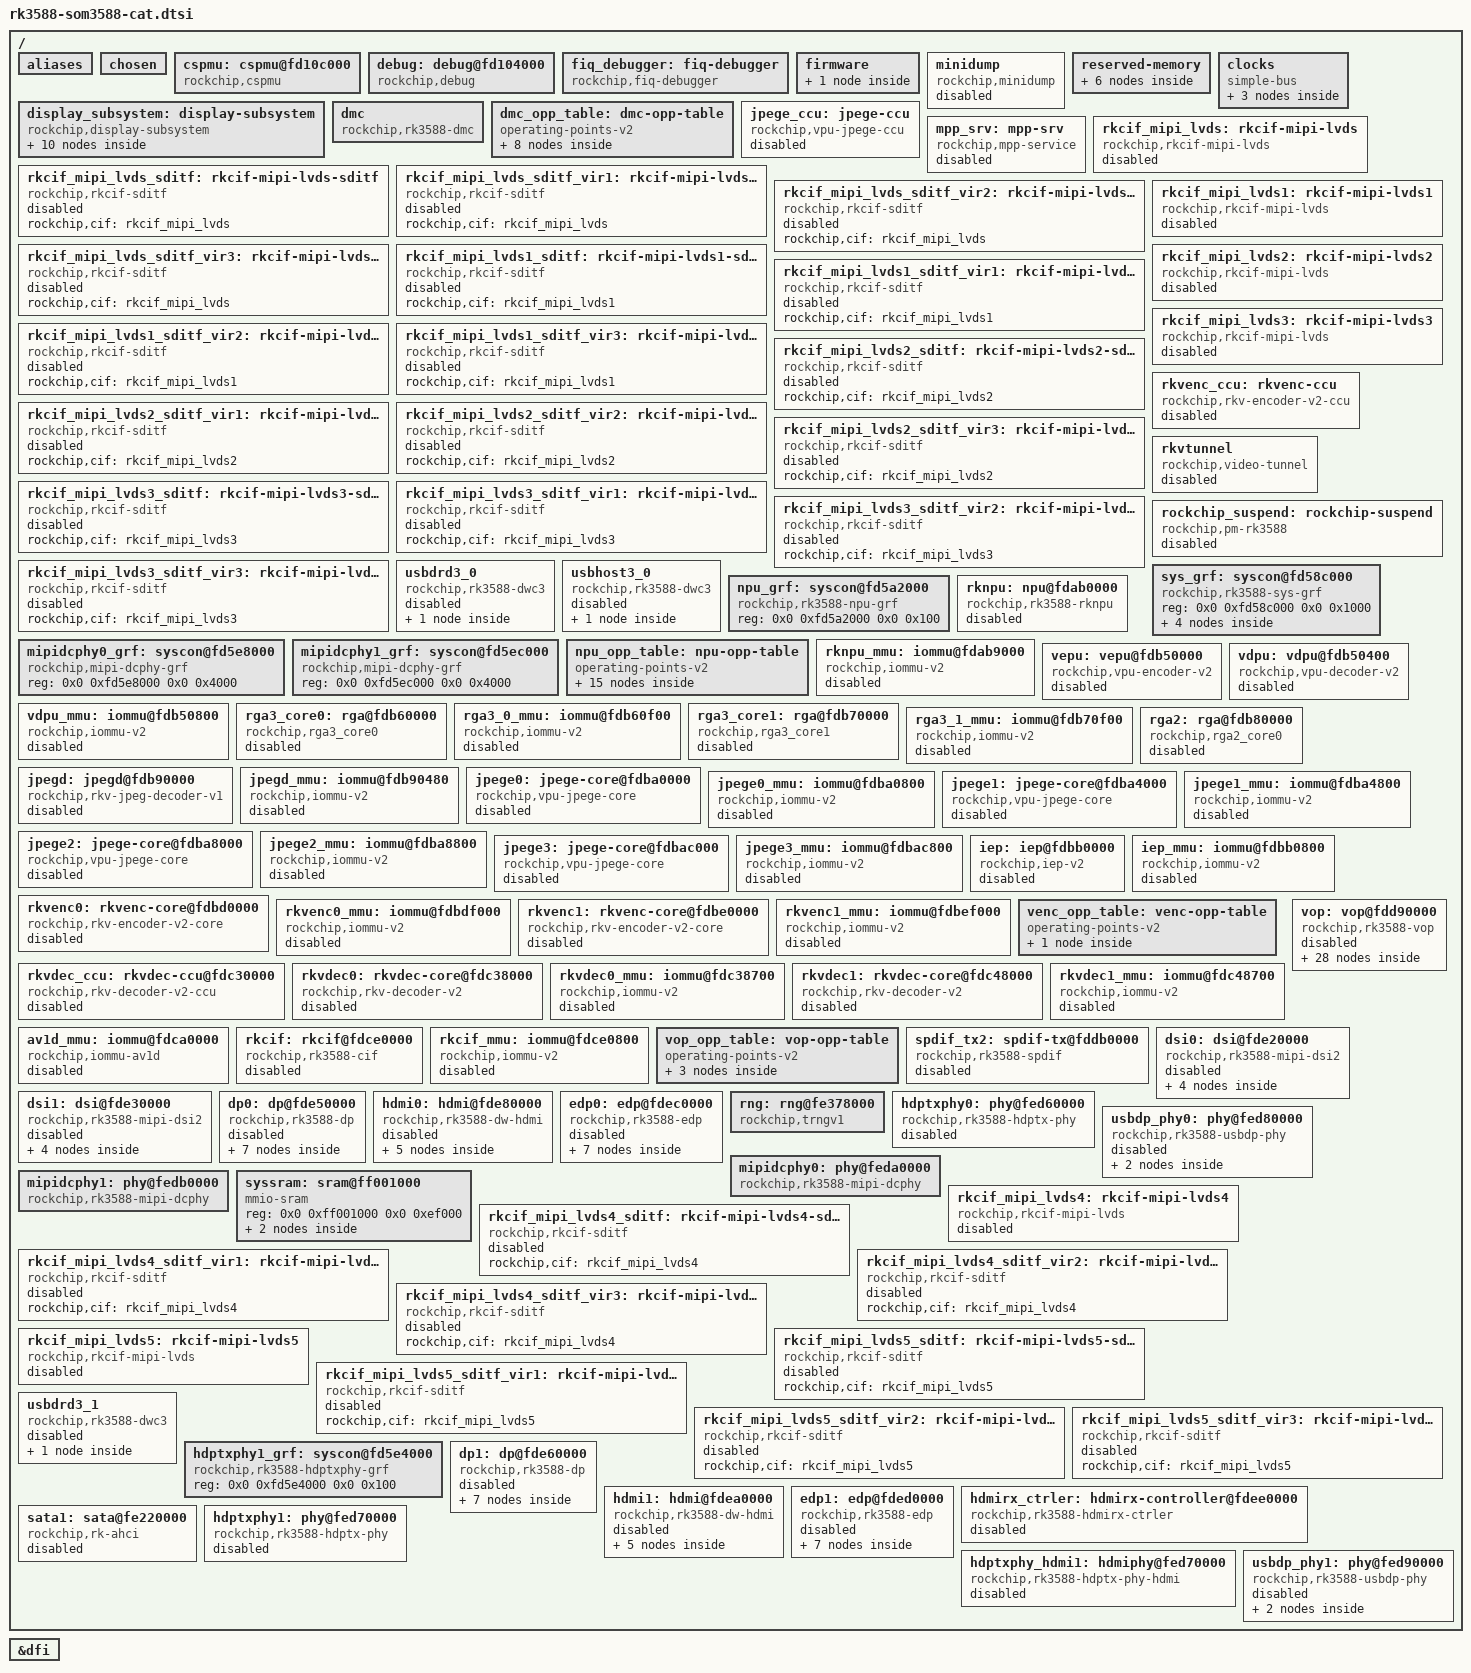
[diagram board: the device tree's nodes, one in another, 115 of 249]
// SPDX-License-Identifier: (GPL-2.0+ OR MIT)
/*
 * Copyright (c) 2022 Rockchip Electronics Co., Ltd.
 *
 */

#include "rk3588.dtsi"
#include "rk3588-linux.dtsi"
#include <dt-bindings/clock/rk3588-cru.h>
#include <dt-bindings/pinctrl/rockchip.h>
#include <dt-bindings/soc/rockchip,boot-mode.h>
#include <dt-bindings/soc/rockchip-system-status.h>
#include <dt-bindings/suspend/rockchip-rk3588.h>
#include <dt-bindings/phy/phy-snps-pcie3.h>

/ {
	aliases {
		mmc0 = &sdhci;
		mmc1 = &sdmmc;
		mmc2 = &sdio;
		rkcif_mipi_lvds0= &rkcif_mipi_lvds;
		rkcif_mipi_lvds1= &rkcif_mipi_lvds1;
		rkcif_mipi_lvds2= &rkcif_mipi_lvds2;
		rkcif_mipi_lvds3= &rkcif_mipi_lvds3;
		rkvdec0 = &rkvdec0;
		rkvdec1 = &rkvdec1;
		rkvenc0 = &rkvenc0;
		rkvenc1 = &rkvenc1;
		jpege0 = &jpege0;
		jpege1 = &jpege1;
		jpege2 = &jpege2;
		jpege3 = &jpege3;
		dp0 = &dp0;
		dp1 = &dp1;
		edp0 = &edp0;
		edp1 = &edp1;
		ethernet0 = &gmac0;
		hdptx0 = &hdptxphy0;
		hdptx1 = &hdptxphy1;
		hdptxhdmi0 = &hdptxphy_hdmi0;
		hdptxhdmi1 = &hdptxphy_hdmi1;
		hdmi0 = &hdmi0;
		hdmi1 = &hdmi1;
		hdmirx0 = &hdmirx_ctrler;
		rkcif_mipi_lvds4= &rkcif_mipi_lvds4;
		rkcif_mipi_lvds5= &rkcif_mipi_lvds5;
		usbdp0 = &usbdp_phy0;
		usbdp1 = &usbdp_phy1;
	};

	chosen: chosen {
		stdout-path = "serial2:1500000n8";
		bootargs = "earlycon=uart8250,mmio32,0xfeb50000 console=ttyFIQ0 irqchip.gicv3_pseudo_nmi=0 root=PARTUUID=614e0000-0000 rw rootwait rcupdate.rcu_expedited=1 rcu_nocbs=all";
	};

	cspmu: cspmu@fd10c000 {
		compatible = "rockchip,cspmu";
		reg = <0x0 0xfd10c000 0x0 0x1000>,
		      <0x0 0xfd10d000 0x0 0x1000>,
		      <0x0 0xfd10e000 0x0 0x1000>,
		      <0x0 0xfd10f000 0x0 0x1000>,
		      <0x0 0xfd12c000 0x0 0x1000>,
		      <0x0 0xfd12d000 0x0 0x1000>,
		      <0x0 0xfd12e000 0x0 0x1000>,
		      <0x0 0xfd12f000 0x0 0x1000>;
	};

	debug: debug@fd104000 {
		compatible = "rockchip,debug";
		reg = <0x0 0xfd104000 0x0 0x1000>,
		      <0x0 0xfd105000 0x0 0x1000>,
		      <0x0 0xfd106000 0x0 0x1000>,
		      <0x0 0xfd107000 0x0 0x1000>,
		      <0x0 0xfd124000 0x0 0x1000>,
		      <0x0 0xfd125000 0x0 0x1000>,
		      <0x0 0xfd126000 0x0 0x1000>,
		      <0x0 0xfd127000 0x0 0x1000>;
	};

	fiq_debugger: fiq-debugger {
		compatible = "rockchip,fiq-debugger";
		rockchip,serial-id = <2>;
		rockchip,wake-irq = <0>;
		/* If enable uart uses irq instead of fiq */
		rockchip,irq-mode-enable = <1>;
		rockchip,baudrate = <1500000>;  /* Only 115200 and 1500000 */
		interrupts = <GIC_SPI 423 IRQ_TYPE_LEVEL_LOW>;
		pinctrl-names = "default";
		pinctrl-0 = <&uart2m0_xfer>;
		status = "okay";
	};

	firmware {
		optee: optee {
			compatible = "linaro,optee-tz";
			method = "smc";
			//status = "disabled";
		};
	};

	minidump: minidump {
		compatible = "rockchip,minidump";
		smem-region = <&minidump_smem>;
		minidump-region = <&minidump_mem>;
		status = "disabled";
	};

	reserved-memory {
		#address-cells = <2>;
		#size-cells = <2>;
		ranges;

		cma {
			compatible = "shared-dma-pool";
			reusable;
			size = <0x0 (8 * 0x100000)>;
			linux,cma-default;
		};

		drm_logo: drm-logo@0 {
			compatible = "rockchip,drm-logo";
			reg = <0x0 0x0 0x0 0x0>;
		};

		drm_cubic_lut: drm-cubic-lut@0 {
			compatible = "rockchip,drm-cubic-lut";
			reg = <0x0 0x0 0x0 0x0>;
		};

		ramoops: ramoops@110000 {
			compatible = "ramoops";
			/* 0x110000 to 0x1f0000 is for ramoops */
			reg = <0x0 0x110000 0x0 0xe0000>;
			boot-log-size = <0x8000>;	/* do not change */
			boot-log-count = <0x1>;		/* do not change */
			console-size = <0x80000>;
			pmsg-size = <0x30000>;
			ftrace-size = <0x00000>;
			record-size = <0x14000>;
		};

		minidump_smem: minidump-smem@1f0000 {
			reg = <0x0 0x1f0000 0x0 0x100>;		/* do not change */
			no-map;
			status = "disabled";
		};

		minidump_mem: minidump-mem@c000000 {
			reg = <0x0 0x0c000000 0x0 0x2000000>;	/* changing according to your project */
			no-map;
			status = "disabled";
		};

	};

	clocks {
		compatible = "simple-bus";
		#address-cells = <2>;
		#size-cells = <2>;
		ranges;

		hclk_vo1: hclk_vo1@fd7c08ec {
			compatible = "rockchip,rk3588-clock-gate-link";
			reg = <0 0xfd7c08ec 0 0x10>;
			clock-names = "link";
			clocks = <&cru HCLK_VO1USB_TOP_ROOT>;
			#power-domain-cells = <1>;
			#clock-cells = <0>;
		};

		hclk_vo0: hclk_vo0@fd7c08dc {
			compatible = "rockchip,rk3588-clock-gate-link";
			reg = <0 0xfd7c08dc 0 0x10>;
			clock-names = "link";
			clocks = <&cru HCLK_VOP_ROOT>;
			#power-domain-cells = <1>;
			#clock-cells = <0>;
		};

		mclkout_i2s0: mclkout-i2s0@fd58c318 {
			compatible = "rockchip,clk-out";
			reg = <0 0xfd58c318 0 0x4>;
			clocks = <&cru I2S0_8CH_MCLKOUT>;
			#clock-cells = <0>;
			clock-output-names = "i2s0_mclkout_to_io";
			power-domains = <&power RK3588_PD_AUDIO>;
			rockchip,bit-shift = <0>;
			rockchip,bit-set-to-disable;
		};
	};

	display_subsystem: display-subsystem {
		compatible = "rockchip,display-subsystem";
		ports = <&vop_out>;

		route {
			route_dp0: route-dp0 {
				status = "disabled";
				logo,uboot = "logo.bmp";
				logo,kernel = "logo_kernel.bmp";
				logo,mode = "center";
				charge_logo,mode = "center";
				connect = <&vp1_out_dp0>;
			};

			route_dsi0: route-dsi0 {
				status = "disabled";
				logo,uboot = "logo.bmp";
				logo,kernel = "logo_kernel.bmp";
				logo,mode = "center";
				charge_logo,mode = "center";
				connect = <&vp3_out_dsi0>;
			};

			route_dsi1: route-dsi1 {
				status = "disabled";
				logo,uboot = "logo.bmp";
				logo,kernel = "logo_kernel.bmp";
				logo,mode = "center";
				charge_logo,mode = "center";
				connect = <&vp3_out_dsi1>;
			};

			route_edp0: route-edp0 {
				status = "disabled";
				logo,uboot = "logo.bmp";
				logo,kernel = "logo_kernel.bmp";
				logo,mode = "center";
				charge_logo,mode = "center";
				connect = <&vp2_out_edp0>;
			};

			route_edp1: route-edp1 {
				status = "disabled";
				logo,uboot = "logo.bmp";
				logo,kernel = "logo_kernel.bmp";
				logo,mode = "center";
				charge_logo,mode = "center";
			};

			route_hdmi0: route-hdmi0 {
				status = "disabled";
				logo,uboot = "logo.bmp";
				logo,kernel = "logo_kernel.bmp";
				logo,mode = "center";
				charge_logo,mode = "center";
				connect = <&vp0_out_hdmi0>;
			};

			route_rgb: route-rgb {
				status = "disabled";
				logo,uboot = "logo.bmp";
				logo,kernel = "logo_kernel.bmp";
				logo,mode = "center";
				charge_logo,mode = "center";
				connect = <&vp3_out_rgb>;
			};
		};
	};

	dmc: dmc {
		compatible = "rockchip,rk3588-dmc";
		interrupts = <GIC_SPI 73 IRQ_TYPE_LEVEL_HIGH>;
		interrupt-names = "complete";
		devfreq-events = <&dfi>;
		clocks = <&scmi_clk 4>;
		clock-names = "dmc_clk";
		operating-points-v2 = <&dmc_opp_table>;
		upthreshold = <25>;
		downdifferential = <20>;
		system-status-level = <
			/*system status         freq level*/
			SYS_STATUS_NORMAL       DMC_FREQ_LEVEL_MID_HIGH
			SYS_STATUS_REBOOT       DMC_FREQ_LEVEL_HIGH
			SYS_STATUS_SUSPEND      DMC_FREQ_LEVEL_LOW
			SYS_STATUS_VIDEO_4K     DMC_FREQ_LEVEL_MID_HIGH
			SYS_STATUS_VIDEO_4K_10B DMC_FREQ_LEVEL_MID_HIGH
			SYS_STATUS_VIDEO_SVEP   DMC_FREQ_LEVEL_MID_HIGH
			SYS_STATUS_BOOST        DMC_FREQ_LEVEL_HIGH
			SYS_STATUS_ISP          DMC_FREQ_LEVEL_HIGH
			SYS_STATUS_PERFORMANCE  DMC_FREQ_LEVEL_HIGH
			SYS_STATUS_DUALVIEW     DMC_FREQ_LEVEL_HIGH
			SYS_STATUS_HDMIRX       DMC_FREQ_LEVEL_HIGH
			SYS_STATUS_DEEP_SUSPEND DMC_FREQ_LEVEL_HIGH
		>;
		auto-freq-en = <1>;
		status = "disabled";
	};

	dmc_opp_table: dmc-opp-table {
		compatible = "operating-points-v2";

		nvmem-cells = <&log_leakage>, <&dmc_opp_info>, <&specification_serial_number>;
		nvmem-cell-names = "leakage", "opp-info", "specification_serial_number";
		rockchip,supported-hw;

		rockchip,leakage-voltage-sel = <
			1	31	0
			32	44	1
			45	57	2
			58	254	3
		>;
		rockchip,temp-hysteresis = <5000>;
		rockchip,low-temp = <15000>;
		rockchip,low-temp-min-volt = <750000>;

		/* RK3588 dmc OPPs */
		opp-528000000 {
			opp-supported-hw = <0xf9 0xffff>;
			opp-hz = /bits/ 64 <528000000>;
			opp-microvolt = <675000 675000 875000>,
					<725000 725000 800000>;
			opp-microvolt-L1 = <675000 675000 875000>,
					   <700000 700000 800000>;
			opp-microvolt-L2 = <675000 675000 875000>,
					   <687500 687500 800000>;
			opp-microvolt-L3 = <675000 675000 875000>,
					   <675000 675000 800000>;
		};
		opp-1068000000 {
			opp-supported-hw = <0xf9 0xffff>;
			opp-hz = /bits/ 64 <1068000000>;
			opp-microvolt = <725000 725000 875000>,
					<737500 737500 800000>;
			opp-microvolt-L1 = <700000 700000 875000>,
					   <712500 712500 800000>;
			opp-microvolt-L2 = <675000 675000 875000>,
					   <700000 700000 800000>;
			opp-microvolt-L3 = <675000 675000 875000>,
					   <687500 687500 800000>;
		};
		opp-1560000000 {
			opp-supported-hw = <0xf9 0xffff>;
			opp-hz = /bits/ 64 <1560000000>;
			opp-microvolt = <800000 800000 875000>,
					<750000 750000 800000>;
			opp-microvolt-L1 = <775000 775000 875000>,
					   <725000 725000 800000>;
			opp-microvolt-L2 = <750000 750000 875000>,
					   <712500 712500 800000>;
			opp-microvolt-L3 = <725000 725000 875000>,
					   <700000 700000 800000>;
		};
		opp-2750000000 {
			opp-supported-hw = <0xf9 0xffff>;
			opp-hz = /bits/ 64 <2750000000>;
			opp-microvolt = <875000 875000 875000>,
					<750000 750000 800000>;
			opp-microvolt-L1 = <850000 850000 875000>,
					   <750000 750000 800000>;
			opp-microvolt-L2 = <837500 837500 875000>,
					   <725000 725000 800000>;
			opp-microvolt-L3 = <825000 820000 875000>,
					   <700000 700000 800000>;
		};

		/* RK3588J/M dmc OPPs */
		opp-j-m-528000000 {
			opp-supported-hw = <0x06 0xffff>;
			opp-hz = /bits/ 64 <528000000>;
			opp-microvolt = <750000 750000 875000>,
					<750000 750000 800000>;
		};
		opp-j-m-1068000000 {
			opp-supported-hw = <0x06 0xffff>;
			opp-hz = /bits/ 64 <1068000000>;
			opp-microvolt = <750000 750000 875000>,
					<750000 750000 800000>;
		};
		opp-j-m-1560000000 {
			opp-supported-hw = <0x06 0xffff>;
			opp-hz = /bits/ 64 <1560000000>;
			opp-microvolt = <800000 800000 875000>,
					<750000 750000 800000>;
			opp-microvolt-L1 = <775000 775000 875000>,
					   <750000 750000 800000>;
			opp-microvolt-L2 = <750000 750000 875000>,
					   <750000 750000 800000>;
			opp-microvolt-L3 = <750000 750000 875000>,
					   <750000 750000 800000>;
		};
		opp-j-m-2750000000 {
			opp-supported-hw = <0x06 0xffff>;
			opp-hz = /bits/ 64 <2750000000>;
			opp-microvolt = <875000 875000 875000>,
					<750000 750000 800000>;
			opp-microvolt-L1 = <850000 850000 875000>,
					   <750000 750000 800000>;
			opp-microvolt-L2 = <837500 837500 875000>,
					   <750000 750000 800000>;
			opp-microvolt-L3 = <825000 820000 875000>,
					   <750000 750000 800000>;
		};
	};

	jpege_ccu: jpege-ccu {
		compatible = "rockchip,vpu-jpege-ccu";
		status = "disabled";
	};

	mpp_srv: mpp-srv {
		compatible = "rockchip,mpp-service";
		rockchip,taskqueue-count = <12>;
		rockchip,resetgroup-count = <1>;
		status = "disabled";
	};

	rkcif_mipi_lvds: rkcif-mipi-lvds {
		compatible = "rockchip,rkcif-mipi-lvds";
		rockchip,hw = <&rkcif>;
		iommus = <&rkcif_mmu>;
		status = "disabled";
	};

	rkcif_mipi_lvds_sditf: rkcif-mipi-lvds-sditf {
		compatible = "rockchip,rkcif-sditf";
		rockchip,cif = <&rkcif_mipi_lvds>;
		status = "disabled";
	};

	rkcif_mipi_lvds_sditf_vir1: rkcif-mipi-lvds-sditf-vir1 {
		compatible = "rockchip,rkcif-sditf";
		rockchip,cif = <&rkcif_mipi_lvds>;
		status = "disabled";
	};

	rkcif_mipi_lvds_sditf_vir2: rkcif-mipi-lvds-sditf-vir2 {
		compatible = "rockchip,rkcif-sditf";
		rockchip,cif = <&rkcif_mipi_lvds>;
		status = "disabled";
	};

	rkcif_mipi_lvds_sditf_vir3: rkcif-mipi-lvds-sditf-vir3 {
		compatible = "rockchip,rkcif-sditf";
		rockchip,cif = <&rkcif_mipi_lvds>;
		status = "disabled";
	};

	rkcif_mipi_lvds1: rkcif-mipi-lvds1 {
		compatible = "rockchip,rkcif-mipi-lvds";
		rockchip,hw = <&rkcif>;
		iommus = <&rkcif_mmu>;
		status = "disabled";
	};

	rkcif_mipi_lvds1_sditf: rkcif-mipi-lvds1-sditf {
		compatible = "rockchip,rkcif-sditf";
		rockchip,cif = <&rkcif_mipi_lvds1>;
		status = "disabled";
	};

	rkcif_mipi_lvds1_sditf_vir1: rkcif-mipi-lvds1-sditf-vir1 {
		compatible = "rockchip,rkcif-sditf";
		rockchip,cif = <&rkcif_mipi_lvds1>;
		status = "disabled";
	};

	rkcif_mipi_lvds1_sditf_vir2: rkcif-mipi-lvds1-sditf-vir2 {
		compatible = "rockchip,rkcif-sditf";
		rockchip,cif = <&rkcif_mipi_lvds1>;
		status = "disabled";
	};

	rkcif_mipi_lvds1_sditf_vir3: rkcif-mipi-lvds1-sditf-vir3 {
		compatible = "rockchip,rkcif-sditf";
		rockchip,cif = <&rkcif_mipi_lvds1>;
		status = "disabled";
	};

	rkcif_mipi_lvds2: rkcif-mipi-lvds2 {
		compatible = "rockchip,rkcif-mipi-lvds";
		rockchip,hw = <&rkcif>;
		iommus = <&rkcif_mmu>;
		status = "disabled";
	};

	rkcif_mipi_lvds2_sditf: rkcif-mipi-lvds2-sditf {
		compatible = "rockchip,rkcif-sditf";
		rockchip,cif = <&rkcif_mipi_lvds2>;
		status = "disabled";
	};

	rkcif_mipi_lvds2_sditf_vir1: rkcif-mipi-lvds2-sditf-vir1 {
		compatible = "rockchip,rkcif-sditf";
		rockchip,cif = <&rkcif_mipi_lvds2>;
		status = "disabled";
	};

	rkcif_mipi_lvds2_sditf_vir2: rkcif-mipi-lvds2-sditf-vir2 {
		compatible = "rockchip,rkcif-sditf";
		rockchip,cif = <&rkcif_mipi_lvds2>;
		status = "disabled";
	};

	rkcif_mipi_lvds2_sditf_vir3: rkcif-mipi-lvds2-sditf-vir3 {
		compatible = "rockchip,rkcif-sditf";
		rockchip,cif = <&rkcif_mipi_lvds2>;
		status = "disabled";
	};

	rkcif_mipi_lvds3: rkcif-mipi-lvds3 {
		compatible = "rockchip,rkcif-mipi-lvds";
		rockchip,hw = <&rkcif>;
		iommus = <&rkcif_mmu>;
		status = "disabled";
	};

	rkcif_mipi_lvds3_sditf: rkcif-mipi-lvds3-sditf {
		compatible = "rockchip,rkcif-sditf";
		rockchip,cif = <&rkcif_mipi_lvds3>;
		status = "disabled";
	};

	rkcif_mipi_lvds3_sditf_vir1: rkcif-mipi-lvds3-sditf-vir1 {
		compatible = "rockchip,rkcif-sditf";
		rockchip,cif = <&rkcif_mipi_lvds3>;
		status = "disabled";
	};

	rkcif_mipi_lvds3_sditf_vir2: rkcif-mipi-lvds3-sditf-vir2 {
		compatible = "rockchip,rkcif-sditf";
		rockchip,cif = <&rkcif_mipi_lvds3>;
		status = "disabled";
	};

	rkcif_mipi_lvds3_sditf_vir3: rkcif-mipi-lvds3-sditf-vir3 {
		compatible = "rockchip,rkcif-sditf";
		rockchip,cif = <&rkcif_mipi_lvds3>;
		status = "disabled";
	};

	rkvenc_ccu: rkvenc-ccu {
		compatible = "rockchip,rkv-encoder-v2-ccu";
		status = "disabled";
	};

	rkvtunnel: rkvtunnel {
		compatible = "rockchip,video-tunnel";
		status = "disabled";
	};

	rockchip_suspend: rockchip-suspend {
		compatible = "rockchip,pm-rk3588";
		status = "disabled";
		rockchip,sleep-debug-en = <0>;
		rockchip,sleep-mode-config = <
			(0
			| RKPM_SLP_ARMOFF_LOGOFF
			| RKPM_SLP_PMU_PMUALIVE_32K
			| RKPM_SLP_PMU_DIS_OSC
			| RKPM_SLP_32K_EXT
			)
		>;
		rockchip,wakeup-config = <
			(0
			| RKPM_GPIO_WKUP_EN
			)
		>;
		power-domains = <&power RK3588_PD_USB>;
	};

	usbdrd3_0: usbdrd3_0 {
		compatible = "rockchip,rk3588-dwc3", "rockchip,rk3399-dwc3";
		clocks = <&cru REF_CLK_USB3OTG0>, <&cru SUSPEND_CLK_USB3OTG0>,
			 <&cru ACLK_USB3OTG0>;
		clock-names = "ref", "suspend", "bus";
		#address-cells = <2>;
		#size-cells = <2>;
		ranges;
		status = "disabled";

		usbdrd_dwc3_0: usb@fc000000 {
			compatible = "snps,dwc3";
			reg = <0x0 0xfc000000 0x0 0x400000>;
			interrupts = <GIC_SPI 220 IRQ_TYPE_LEVEL_HIGH>;
			power-domains = <&power RK3588_PD_USB>;
			resets = <&cru SRST_A_USB3OTG0>;
			reset-names = "usb3-otg";
			dr_mode = "otg";
			phys = <&u2phy0_otg>, <&usbdp_phy0_u3>;
			phy-names = "usb2-phy", "usb3-phy";
			phy_type = "utmi_wide";
			snps,dis_enblslpm_quirk;
			snps,dis-u1-entry-quirk;
			snps,dis-u2-entry-quirk;
			snps,dis-u2-freeclk-exists-quirk;
			snps,dis-del-phy-power-chg-quirk;
			snps,dis-tx-ipgap-linecheck-quirk;
			snps,parkmode-disable-hs-quirk;
			snps,parkmode-disable-ss-quirk;
			quirk-skip-phy-init;
			status = "disabled";
		};
	};

	usbhost3_0: usbhost3_0 {
		compatible = "rockchip,rk3588-dwc3", "rockchip,rk3399-dwc3";
		clocks = <&cru REF_CLK_USB3OTG2>, <&cru SUSPEND_CLK_USB3OTG2>,
			 <&cru ACLK_USB3OTG2>, <&cru CLK_UTMI_OTG2>,
			 <&cru PCLK_PHP_ROOT>, <&cru CLK_PIPEPHY2_PIPE_U3_G>;
		clock-names = "ref", "suspend", "bus", "utmi", "php", "pipe";
		#address-cells = <2>;
		#size-cells = <2>;
		ranges;
		status = "disabled";

		usbhost_dwc3_0: usb@fcd00000 {
			compatible = "snps,dwc3";
			reg = <0x0 0xfcd00000 0x0 0x400000>;
			interrupts = <GIC_SPI 222 IRQ_TYPE_LEVEL_HIGH>;
			resets = <&cru SRST_A_USB3OTG2>;
			reset-names = "usb3-host";
			dr_mode = "host";
			phys = <&combphy2_psu PHY_TYPE_USB3>;
			phy-names = "usb3-phy";
			phy_type = "utmi_wide";
			snps,dis_enblslpm_quirk;
			snps,dis-u2-freeclk-exists-quirk;
			snps,dis-del-phy-power-chg-quirk;
			snps,dis-tx-ipgap-linecheck-quirk;
			snps,dis_rxdet_inp3_quirk;
			snps,parkmode-disable-hs-quirk;
			snps,parkmode-disable-ss-quirk;
			status = "disabled";
		};
	};

	sys_grf: syscon@fd58c000 {
		compatible = "rockchip,rk3588-sys-grf", "syscon", "simple-mfd";
		reg = <0x0 0xfd58c000 0x0 0x1000>;

		rgb: rgb {
			compatible = "rockchip,rk3588-rgb";
			pinctrl-names = "default";
			pinctrl-0 = <&bt1120_pins>;
			status = "disabled";

			ports {
				#address-cells = <1>;
				#size-cells = <0>;

				port@0 {
					reg = <0>;
					#address-cells = <1>;
					#size-cells = <0>;

					rgb_in_vp3: endpoint@2 {
						reg = <2>;
						remote-endpoint = <&vp3_out_rgb>;
						status = "disabled";
					};
				};
			};
		};
	};
	
	npu_grf: syscon@fd5a2000 {
		compatible = "rockchip,rk3588-npu-grf", "syscon";
		reg = <0x0 0xfd5a2000 0x0 0x100>;
	};

	mipidcphy0_grf: syscon@fd5e8000 {
		compatible = "rockchip,mipi-dcphy-grf", "syscon";
		reg = <0x0 0xfd5e8000 0x0 0x4000>;
	};

	mipidcphy1_grf: syscon@fd5ec000 {
		compatible = "rockchip,mipi-dcphy-grf", "syscon";
		reg = <0x0 0xfd5ec000 0x0 0x4000>;
	};

	rknpu: npu@fdab0000 {
		compatible = "rockchip,rk3588-rknpu";
		reg = <0x0 0xfdab0000 0x0 0x10000>,
		      <0x0 0xfdac0000 0x0 0x10000>,
		      <0x0 0xfdad0000 0x0 0x10000>;
		interrupts = <GIC_SPI 110 IRQ_TYPE_LEVEL_HIGH>,
			     <GIC_SPI 111 IRQ_TYPE_LEVEL_HIGH>,
			     <GIC_SPI 112 IRQ_TYPE_LEVEL_HIGH>;
		interrupt-names = "npu0_irq", "npu1_irq", "npu2_irq";
		clocks = <&scmi_clk SCMI_CLK_NPU>, <&cru ACLK_NPU0>,
			 <&cru ACLK_NPU1>, <&cru ACLK_NPU2>,
			 <&cru HCLK_NPU0>, <&cru HCLK_NPU1>,
			 <&cru HCLK_NPU2>, <&cru PCLK_NPU_ROOT>;
		clock-names = "clk_npu", "aclk0",
			      "aclk1", "aclk2",
			      "hclk0", "hclk1",
			      "hclk2", "pclk";
		assigned-clocks = <&scmi_clk SCMI_CLK_NPU>;
		assigned-clock-rates = <200000000>;
		resets = <&cru SRST_A_RKNN0>, <&cru SRST_A_RKNN1>, <&cru SRST_A_RKNN2>,
			 <&cru SRST_H_RKNN0>, <&cru SRST_H_RKNN1>, <&cru SRST_H_RKNN2>;
		reset-names = "srst_a0", "srst_a1", "srst_a2",
			      "srst_h0", "srst_h1", "srst_h2";
		power-domains = <&power RK3588_PD_NPUTOP>,
				<&power RK3588_PD_NPU1>,
				<&power RK3588_PD_NPU2>;
		power-domain-names = "npu0", "npu1", "npu2";
		operating-points-v2 = <&npu_opp_table>;
		iommus = <&rknpu_mmu>;
		status = "disabled";
	};

	rknpu: npu@fdab0000 {
		compatible = "rockchip,rk3588-rknpu";
		reg = <0x0 0xfdab0000 0x0 0x10000>,
		      <0x0 0xfdac0000 0x0 0x10000>,
		      <0x0 0xfdad0000 0x0 0x10000>;
		interrupts = <GIC_SPI 110 IRQ_TYPE_LEVEL_HIGH>,
			     <GIC_SPI 111 IRQ_TYPE_LEVEL_HIGH>,
			     <GIC_SPI 112 IRQ_TYPE_LEVEL_HIGH>;
		interrupt-names = "npu0_irq", "npu1_irq", "npu2_irq";
		clocks = <&scmi_clk SCMI_CLK_NPU>, <&cru ACLK_NPU0>,
			 <&cru ACLK_NPU1>, <&cru ACLK_NPU2>,
			 <&cru HCLK_NPU0>, <&cru HCLK_NPU1>,
			 <&cru HCLK_NPU2>, <&cru PCLK_NPU_ROOT>;
		clock-names = "clk_npu", "aclk0",
			      "aclk1", "aclk2",
			      "hclk0", "hclk1",
			      "hclk2", "pclk";
		assigned-clocks = <&scmi_clk SCMI_CLK_NPU>;
		assigned-clock-rates = <200000000>;
		resets = <&cru SRST_A_RKNN0>, <&cru SRST_A_RKNN1>, <&cru SRST_A_RKNN2>,
			 <&cru SRST_H_RKNN0>, <&cru SRST_H_RKNN1>, <&cru SRST_H_RKNN2>;
		reset-names = "srst_a0", "srst_a1", "srst_a2",
			      "srst_h0", "srst_h1", "srst_h2";
		power-domains = <&power RK3588_PD_NPUTOP>,
				<&power RK3588_PD_NPU1>,
				<&power RK3588_PD_NPU2>;
		power-domain-names = "npu0", "npu1", "npu2";
		operating-points-v2 = <&npu_opp_table>;
		iommus = <&rknpu_mmu>;
		status = "disabled";
	};

	npu_opp_table: npu-opp-table {
		compatible = "operating-points-v2";

		nvmem-cells = <&npu_leakage>, <&npu_opp_info>, <&specification_serial_number>;
		nvmem-cell-names = "leakage", "opp-info", "specification_serial_number";
		rockchip,supported-hw;

		rockchip,pvtm-hw = <0x06>;
		rockchip,pvtm-voltage-sel-hw = <
			0	799	0
			800	819	1
			820	844	2
			845	869	3
			870	894	4
			895	9999	5
		>;
		rockchip,pvtm-voltage-sel = <
			0	815	0
			816	835	1
			836	860	2
			861	885	3
			886	910	4
			911	9999	5
		>;
		rockchip,pvtm-pvtpll;
		rockchip,pvtm-offset = <0x50>;
		rockchip,pvtm-sample-time = <1100>;
		rockchip,pvtm-freq = <800000>;
		rockchip,pvtm-volt = <750000>;
		rockchip,pvtm-ref-temp = <25>;
		rockchip,pvtm-temp-prop = <(-113) (-113)>;
		rockchip,pvtm-thermal-zone = "npu-thermal";

		rockchip,opp-clocks = <&cru PCLK_NPU_GRF>, <&cru HCLK_NPU_ROOT>;
		rockchip,grf = <&npu_grf>;
		volt-mem-read-margin = <
			855000	1
			765000	2
			675000	3
			495000	4
		>;
		low-volt-mem-read-margin = <4>;
		intermediate-threshold-freq = <500000>;	/* KHz*/
		rockchip,init-freq = <1000000>;		/* KHz */

		rockchip,temp-hysteresis = <5000>;
		rockchip,low-temp = <15000>;
		rockchip,low-temp-min-volt = <750000>;
		rockchip,high-temp = <85000>;
		rockchip,high-temp-max-freq = <800000>;

		/* RK3588 npu OPPs */
		opp-300000000 {
			opp-supported-hw = <0xf9 0xffff>;
			opp-hz = /bits/ 64 <300000000>;
			opp-microvolt = <700000 700000 850000>,
					<700000 700000 850000>;
			opp-microvolt-L1 = <687500 687500 850000>,
					   <687500 687500 850000>;
			opp-microvolt-L2 = <675000 675000 850000>,
					   <675000 675000 850000>;
			opp-microvolt-L3 = <675000 675000 850000>,
					   <675000 675000 850000>;
			opp-microvolt-L4 = <675000 675000 850000>,
					   <675000 675000 850000>;
			opp-microvolt-L5 = <675000 675000 850000>,
					   <675000 675000 850000>;
		};
		opp-400000000 {
			opp-supported-hw = <0xf9 0xffff>;
			opp-hz = /bits/ 64 <400000000>;
			opp-microvolt = <700000 700000 850000>,
					<700000 700000 850000>;
			opp-microvolt-L1 = <687500 687500 850000>,
					   <687500 687500 850000>;
			opp-microvolt-L2 = <675000 675000 850000>,
					   <675000 675000 850000>;
			opp-microvolt-L3 = <675000 675000 850000>,
					   <675000 675000 850000>;
			opp-microvolt-L4 = <675000 675000 850000>,
					   <675000 675000 850000>;
			opp-microvolt-L5 = <675000 675000 850000>,
					   <675000 675000 850000>;
		};
		opp-500000000 {
			opp-supported-hw = <0xf9 0xffff>;
			opp-hz = /bits/ 64 <500000000>;
			opp-microvolt = <700000 700000 850000>,
					<700000 700000 850000>;
			opp-microvolt-L1 = <687500 687500 850000>,
					   <687500 687500 850000>;
			opp-microvolt-L2 = <675000 675000 850000>,
					   <675000 675000 850000>;
			opp-microvolt-L3 = <675000 675000 850000>,
					   <675000 675000 850000>;
			opp-microvolt-L4 = <675000 675000 850000>,
					   <675000 675000 850000>;
			opp-microvolt-L5 = <675000 675000 850000>,
					   <675000 675000 850000>;
		};
		opp-600000000 {
			opp-supported-hw = <0xf9 0xffff>;
			opp-hz = /bits/ 64 <600000000>;
			opp-microvolt = <700000 700000 850000>,
					<700000 700000 850000>;
			opp-microvolt-L1 = <687500 687500 850000>,
					   <687500 687500 850000>;
			opp-microvolt-L2 = <675000 675000 850000>,
					   <675000 675000 850000>;
			opp-microvolt-L3 = <675000 675000 850000>,
					   <675000 675000 850000>;
			opp-microvolt-L4 = <675000 675000 850000>,
					   <675000 675000 850000>;
			opp-microvolt-L5 = <675000 675000 850000>,
					   <675000 675000 850000>;
		};
		opp-700000000 {
			opp-supported-hw = <0xf9 0xffff>;
			opp-hz = /bits/ 64 <700000000>;
			opp-microvolt = <700000 700000 850000>,
					<700000 700000 850000>;
			opp-microvolt-L3 = <687500 687500 850000>,
					   <687500 687500 850000>;
			opp-microvolt-L4 = <675000 675000 850000>,
					   <675000 675000 850000>;
			opp-microvolt-L5 = <675000 675000 850000>,
					   <675000 675000 850000>;
		};
		opp-800000000 {
			opp-supported-hw = <0xf9 0xffff>;
			opp-hz = /bits/ 64 <800000000>;
			opp-microvolt = <750000 750000 850000>,
					<750000 750000 850000>;
			opp-microvolt-L2 = <737500 737500 850000>,
					   <737500 737500 850000>;
			opp-microvolt-L3 = <725000 725000 850000>,
					   <725000 725000 850000>;
			opp-microvolt-L4 = <712500 712500 850000>,
					   <712500 712500 850000>;
			opp-microvolt-L5 = <700000 700000 850000>,
					   <700000 700000 850000>;
		};
		opp-900000000 {
			opp-supported-hw = <0xf9 0xffff>;
			opp-hz = /bits/ 64 <900000000>;
			opp-microvolt = <800000 800000 850000>,
					<800000 800000 850000>;
			opp-microvolt-L1 = <787500 787500 850000>,
					   <787500 787500 850000>;
			opp-microvolt-L2 = <775000 775000 850000>,
					   <775000 775000 850000>;
			opp-microvolt-L3 = <762500 762500 850000>,
					   <762500 762500 850000>;
			opp-microvolt-L4 = <750000 750000 850000>,
					   <750000 750000 850000>;
			opp-microvolt-L5 = <737500 737500 850000>,
					   <737500 737500 850000>;
		};
		opp-1000000000 {
			opp-supported-hw = <0xf9 0xffff>;
			opp-hz = /bits/ 64 <1000000000>;
			opp-microvolt = <850000 850000 850000>,
					<850000 850000 850000>;
			opp-microvolt-L1 = <837500 837500 850000>,
					   <837500 837500 850000>;
			opp-microvolt-L2 = <825000 825000 850000>,
					   <825000 825000 850000>;
			opp-microvolt-L3 = <812500 812500 850000>,
					   <812500 812500 850000>;
			opp-microvolt-L4 = <800000 800000 850000>,
					   <800000 800000 850000>;
			opp-microvolt-L5 = <787500 787500 850000>,
					   <787500 787500 850000>;
		};

		/* RK3588J/M npu OPPs */
		opp-j-m-300000000 {
			opp-supported-hw = <0x06 0xffff>;
			opp-hz = /bits/ 64 <300000000>;
			opp-microvolt = <750000 750000 850000>,
					<750000 750000 850000>;
		};
		opp-j-m-400000000 {
			opp-supported-hw = <0x06 0xffff>;
			opp-hz = /bits/ 64 <400000000>;
			opp-microvolt = <750000 750000 850000>,
					<750000 750000 850000>;
		};
		opp-j-m-500000000 {
			opp-supported-hw = <0x06 0xffff>;
			opp-hz = /bits/ 64 <500000000>;
			opp-microvolt = <750000 750000 850000>,
					<750000 750000 850000>;
		};
		opp-j-m-600000000 {
			opp-supported-hw = <0x06 0xffff>;
			opp-hz = /bits/ 64 <600000000>;
			opp-microvolt = <750000 750000 850000>,
					<750000 750000 850000>;
		};
		opp-j-m-700000000 {
			opp-supported-hw = <0x06 0xffff>;
			opp-hz = /bits/ 64 <700000000>;
			opp-microvolt = <750000 750000 850000>,
					<750000 750000 850000>;
		};
		opp-j-m-800000000 {
			opp-supported-hw = <0x06 0xffff>;
			opp-hz = /bits/ 64 <800000000>;
			opp-microvolt = <750000 750000 850000>,
					<750000 750000 850000>;
		};
		opp-j-m-950000000 {
			opp-supported-hw = <0x06 0xffff>;
			opp-hz = /bits/ 64 <950000000>;
			opp-microvolt = <837500 837500 850000>,
					<837500 837500 850000>;
			opp-microvolt-L1 = <825000 825000 850000>,
					   <825000 825000 850000>;
			opp-microvolt-L2 = <812500 812500 850000>,
					   <812500 812500 850000>;
			opp-microvolt-L3 = <800000 800000 850000>,
					   <800000 800000 850000>;
			opp-microvolt-L4 = <787500 787500 850000>,
					   <787500 787500 850000>;
			opp-microvolt-L5 = <775000 775000 850000>,
					   <775000 775000 850000>;
		};
	};

	rknpu_mmu: iommu@fdab9000 {
		compatible = "rockchip,iommu-v2";
		reg = <0x0 0xfdab9000 0x0 0x100>,
		      <0x0 0xfdaba000 0x0 0x100>,
		      <0x0 0xfdaca000 0x0 0x100>,
		      <0x0 0xfdada000 0x0 0x100>;
		interrupts = <GIC_SPI 110 IRQ_TYPE_LEVEL_HIGH>,
			     <GIC_SPI 111 IRQ_TYPE_LEVEL_HIGH>,
			     <GIC_SPI 112 IRQ_TYPE_LEVEL_HIGH>;
		interrupt-names = "npu0_mmu", "npu1_mmu", "npu2_mmu";
		clocks = <&cru ACLK_NPU0>, <&cru ACLK_NPU1>, <&cru ACLK_NPU2>,
			 <&cru HCLK_NPU0>, <&cru HCLK_NPU1>, <&cru HCLK_NPU2>;
		clock-names = "aclk0", "aclk1", "aclk2",
			      "iface0", "iface1", "iface2";
		#iommu-cells = <0>;
		status = "disabled";
	};

	vepu: vepu@fdb50000 {
		compatible = "rockchip,vpu-encoder-v2";
		reg = <0x0 0xfdb50000 0x0 0x400>;
		interrupts = <GIC_SPI 120 IRQ_TYPE_LEVEL_HIGH>;
		interrupt-names = "irq_vepu";
		clocks = <&cru ACLK_VPU>, <&cru HCLK_VPU>;
		clock-names = "aclk_vcodec", "hclk_vcodec";
		rockchip,normal-rates = <594000000>, <0>;
		assigned-clocks = <&cru ACLK_VPU>;
		assigned-clock-rates = <594000000>;
		resets = <&cru SRST_A_VPU>, <&cru SRST_H_VPU>;
		reset-names = "shared_video_a", "shared_video_h";
		rockchip,skip-pmu-idle-request;
		rockchip,disable-auto-freq;
		iommus = <&vdpu_mmu>;
		rockchip,srv = <&mpp_srv>;
		rockchip,taskqueue-node = <0>;
		rockchip,resetgroup-node = <0>;
		power-domains = <&power RK3588_PD_VDPU>;
		status = "disabled";
	};

	vdpu: vdpu@fdb50400 {
		compatible = "rockchip,vpu-decoder-v2";
		reg = <0x0 0xfdb50400 0x0 0x400>;
		interrupts = <GIC_SPI 119 IRQ_TYPE_LEVEL_HIGH>;
		interrupt-names = "irq_vdpu";
		clocks = <&cru ACLK_VPU>, <&cru HCLK_VPU>;
		clock-names = "aclk_vcodec", "hclk_vcodec";
		rockchip,normal-rates = <594000000>, <0>;
		assigned-clocks = <&cru ACLK_VPU>;
		assigned-clock-rates = <594000000>;
		resets = <&cru SRST_A_VPU>, <&cru SRST_H_VPU>;
		reset-names = "shared_video_a", "shared_video_h";
		rockchip,skip-pmu-idle-request;
		rockchip,disable-auto-freq;
		iommus = <&vdpu_mmu>;
		rockchip,srv = <&mpp_srv>;
		rockchip,taskqueue-node = <0>;
		rockchip,resetgroup-node = <0>;
		power-domains = <&power RK3588_PD_VDPU>;
		status = "disabled";
	};

	vdpu_mmu: iommu@fdb50800 {
		compatible = "rockchip,iommu-v2";
		reg = <0x0 0xfdb50800 0x0 0x40>;
		interrupts = <GIC_SPI 118 IRQ_TYPE_LEVEL_HIGH>;
		interrupt-names = "irq_vdpu_mmu";
		clocks = <&cru ACLK_VPU>, <&cru HCLK_VPU>;
		clock-names = "aclk", "iface";
		power-domains = <&power RK3588_PD_VDPU>;
		#iommu-cells = <0>;
		status = "disabled";
	};

	rga3_core0: rga@fdb60000 {
		compatible = "rockchip,rga3_core0";
		reg = <0x0 0xfdb60000 0x0 0x1000>;
		interrupts = <GIC_SPI 114 IRQ_TYPE_LEVEL_HIGH>;
		interrupt-names = "rga3_core0_irq";
		clocks = <&cru ACLK_RGA3_0>, <&cru HCLK_RGA3_0>, <&cru CLK_RGA3_0_CORE>;
		clock-names = "aclk_rga3_0", "hclk_rga3_0", "clk_rga3_0";
		power-domains = <&power RK3588_PD_RGA30>;
		iommus = <&rga3_0_mmu>;
		status = "disabled";
	};

	rga3_0_mmu: iommu@fdb60f00 {
		compatible = "rockchip,iommu-v2";
		reg = <0x0 0xfdb60f00 0x0 0x100>;
		interrupts = <GIC_SPI 114 IRQ_TYPE_LEVEL_HIGH>;
		interrupt-names = "rga3_0_mmu";
		clocks = <&cru ACLK_RGA3_0>, <&cru HCLK_RGA3_0>;
		clock-names = "aclk", "iface";
		power-domains = <&power RK3588_PD_RGA30>;
		#iommu-cells = <0>;
		status = "disabled";
	};

	rga3_core1: rga@fdb70000 {
		compatible = "rockchip,rga3_core1";
		reg = <0x0 0xfdb70000 0x0 0x1000>;
		interrupts = <GIC_SPI 115 IRQ_TYPE_LEVEL_HIGH>;
		interrupt-names = "rga3_core1_irq";
		clocks = <&cru ACLK_RGA3_1>, <&cru HCLK_RGA3_1>, <&cru CLK_RGA3_1_CORE>;
		clock-names = "aclk_rga3_1", "hclk_rga3_1", "clk_rga3_1";
		power-domains = <&power RK3588_PD_RGA31>;
		iommus = <&rga3_1_mmu>;
		status = "disabled";
	};

	rga3_1_mmu: iommu@fdb70f00 {
		compatible = "rockchip,iommu-v2";
		reg = <0x0 0xfdb70f00 0x0 0x100>;
		interrupts = <GIC_SPI 115 IRQ_TYPE_LEVEL_HIGH>;
		interrupt-names = "rga3_1_mmu";
		clocks = <&cru ACLK_RGA3_1>, <&cru HCLK_RGA3_1>;
		clock-names = "aclk", "iface";
		power-domains = <&power RK3588_PD_RGA31>;
		#iommu-cells = <0>;
		status = "disabled";
	};

	rga2: rga@fdb80000 {
		compatible = "rockchip,rga2_core0";
		reg = <0x0 0xfdb80000 0x0 0x1000>;
		interrupts = <GIC_SPI 116 IRQ_TYPE_LEVEL_HIGH>;
		interrupt-names = "rga2_irq";
		clocks = <&cru ACLK_RGA2>, <&cru HCLK_RGA2>, <&cru CLK_RGA2_CORE>;
		clock-names = "aclk_rga2", "hclk_rga2", "clk_rga2";
		power-domains = <&power RK3588_PD_VDPU>;
		status = "disabled";
	};

	jpegd: jpegd@fdb90000 {
		compatible = "rockchip,rkv-jpeg-decoder-v1";
		reg = <0x0 0xfdb90000 0x0 0x400>;
		interrupts = <GIC_SPI 129 IRQ_TYPE_LEVEL_HIGH>;
		interrupt-names = "irq_jpegd";
		clocks = <&cru ACLK_JPEG_DECODER>, <&cru HCLK_JPEG_DECODER>;
		clock-names = "aclk_vcodec", "hclk_vcodec";
		rockchip,normal-rates = <600000000>, <0>;
		assigned-clocks = <&cru ACLK_JPEG_DECODER>;
		assigned-clock-rates = <600000000>;
		resets = <&cru SRST_A_JPEG_DECODER>, <&cru SRST_H_JPEG_DECODER>;
		reset-names = "video_a", "video_h";
		rockchip,skip-pmu-idle-request;
		iommus = <&jpegd_mmu>;
		rockchip,srv = <&mpp_srv>;
		rockchip,taskqueue-node = <1>;
		power-domains = <&power RK3588_PD_VDPU>;
		status = "disabled";
	};

	jpegd_mmu: iommu@fdb90480 {
		compatible = "rockchip,iommu-v2";
		reg = <0x0 0xfdb90480 0x0 0x40>;
		interrupts = <GIC_SPI 130 IRQ_TYPE_LEVEL_HIGH>;
		interrupt-names = "irq_jpegd_mmu";
		clocks = <&cru ACLK_JPEG_DECODER>, <&cru HCLK_JPEG_DECODER>;
		clock-names = "aclk", "iface";
		power-domains = <&power RK3588_PD_VDPU>;
		#iommu-cells = <0>;
		status = "disabled";
	};

	jpege0: jpege-core@fdba0000 {
		compatible = "rockchip,vpu-jpege-core";
		reg = <0x0 0xfdba0000 0x0 0x400>;
		interrupts = <GIC_SPI 122 IRQ_TYPE_LEVEL_HIGH>;
		interrupt-names = "irq_jpege0";
		clocks = <&cru ACLK_JPEG_ENCODER0>, <&cru HCLK_JPEG_ENCODER0>;
		clock-names = "aclk_vcodec", "hclk_vcodec";
		rockchip,normal-rates = <594000000>, <0>;
		assigned-clocks = <&cru ACLK_JPEG_ENCODER0>;
		assigned-clock-rates = <594000000>;
		resets = <&cru SRST_A_JPEG_ENCODER0>, <&cru SRST_H_JPEG_ENCODER0>;
		reset-names = "video_a", "video_h";
		rockchip,skip-pmu-idle-request;
		rockchip,disable-auto-freq;
		iommus = <&jpege0_mmu>;
		rockchip,srv = <&mpp_srv>;
		rockchip,taskqueue-node = <2>;
		rockchip,ccu = <&jpege_ccu>;
		power-domains = <&power RK3588_PD_VDPU>;
		status = "disabled";
	};

	jpege0_mmu: iommu@fdba0800 {
		compatible = "rockchip,iommu-v2";
		reg = <0x0 0xfdba0800 0x0 0x40>;
		interrupts = <GIC_SPI 121 IRQ_TYPE_LEVEL_HIGH>;
		interrupt-names = "irq_jpege0_mmu";
		clocks = <&cru ACLK_JPEG_ENCODER0>, <&cru HCLK_JPEG_ENCODER0>;
		clock-names = "aclk", "iface";
		power-domains = <&power RK3588_PD_VDPU>;
		#iommu-cells = <0>;
		status = "disabled";
	};

	jpege1: jpege-core@fdba4000 {
		compatible = "rockchip,vpu-jpege-core";
		reg = <0x0 0xfdba4000 0x0 0x400>;
		interrupts = <GIC_SPI 124 IRQ_TYPE_LEVEL_HIGH>;
		interrupt-names = "irq_jpege1";
		clocks = <&cru ACLK_JPEG_ENCODER1>, <&cru HCLK_JPEG_ENCODER1>;
		clock-names = "aclk_vcodec", "hclk_vcodec";
		rockchip,normal-rates = <594000000>, <0>;
		assigned-clocks = <&cru ACLK_JPEG_ENCODER1>;
		assigned-clock-rates = <594000000>;
		resets = <&cru SRST_A_JPEG_ENCODER1>, <&cru SRST_H_JPEG_ENCODER1>;
		reset-names = "video_a", "video_h";
		rockchip,skip-pmu-idle-request;
		rockchip,disable-auto-freq;
		iommus = <&jpege1_mmu>;
		rockchip,srv = <&mpp_srv>;
		rockchip,taskqueue-node = <2>;
		rockchip,ccu = <&jpege_ccu>;
		power-domains = <&power RK3588_PD_VDPU>;
		status = "disabled";
	};

	jpege1_mmu: iommu@fdba4800 {
		compatible = "rockchip,iommu-v2";
		reg = <0x0 0xfdba4800 0x0 0x40>;
		interrupts = <GIC_SPI 123 IRQ_TYPE_LEVEL_HIGH>;
		interrupt-names = "irq_jpege1_mmu";
		clocks = <&cru ACLK_JPEG_ENCODER1>, <&cru HCLK_JPEG_ENCODER1>;
		clock-names = "aclk", "iface";
		power-domains = <&power RK3588_PD_VDPU>;
		#iommu-cells = <0>;
		status = "disabled";
	};

	jpege2: jpege-core@fdba8000 {
		compatible = "rockchip,vpu-jpege-core";
		reg = <0x0 0xfdba8000 0x0 0x400>;
		interrupts = <GIC_SPI 126 IRQ_TYPE_LEVEL_HIGH>;
		interrupt-names = "irq_jpege2";
		clocks = <&cru ACLK_JPEG_ENCODER2>, <&cru HCLK_JPEG_ENCODER2>;
		clock-names = "aclk_vcodec", "hclk_vcodec";
		rockchip,normal-rates = <594000000>, <0>;
		assigned-clocks = <&cru ACLK_JPEG_ENCODER2>;
		assigned-clock-rates = <594000000>;
		resets = <&cru SRST_A_JPEG_ENCODER2>, <&cru SRST_H_JPEG_ENCODER2>;
		reset-names = "video_a", "video_h";
		rockchip,skip-pmu-idle-request;
		rockchip,disable-auto-freq;
		iommus = <&jpege2_mmu>;
		rockchip,srv = <&mpp_srv>;
		rockchip,taskqueue-node = <2>;
		rockchip,ccu = <&jpege_ccu>;
		power-domains = <&power RK3588_PD_VDPU>;
		status = "disabled";
	};

	jpege2_mmu: iommu@fdba8800 {
		compatible = "rockchip,iommu-v2";
		reg = <0x0 0xfdba8800 0x0 0x40>;
		interrupts = <GIC_SPI 125 IRQ_TYPE_LEVEL_HIGH>;
		interrupt-names = "irq_jpege2_mmu";
		clocks = <&cru ACLK_JPEG_ENCODER2>, <&cru HCLK_JPEG_ENCODER2>;
		clock-names = "aclk", "iface";
		power-domains = <&power RK3588_PD_VDPU>;
		#iommu-cells = <0>;
		status = "disabled";
	};

	jpege3: jpege-core@fdbac000 {
		compatible = "rockchip,vpu-jpege-core";
		reg = <0x0 0xfdbac000 0x0 0x400>;
		interrupts = <GIC_SPI 128 IRQ_TYPE_LEVEL_HIGH>;
		interrupt-names = "irq_jpege3";
		clocks = <&cru ACLK_JPEG_ENCODER3>, <&cru HCLK_JPEG_ENCODER3>;
		clock-names = "aclk_vcodec", "hclk_vcodec";
		rockchip,normal-rates = <594000000>, <0>;
		assigned-clocks = <&cru ACLK_JPEG_ENCODER3>;
		assigned-clock-rates = <594000000>;
		resets = <&cru SRST_A_JPEG_ENCODER3>, <&cru SRST_H_JPEG_ENCODER3>;
		reset-names = "video_a", "video_h";
		rockchip,skip-pmu-idle-request;
		rockchip,disable-auto-freq;
		iommus = <&jpege3_mmu>;
		rockchip,srv = <&mpp_srv>;
		rockchip,taskqueue-node = <2>;
		rockchip,ccu = <&jpege_ccu>;
		power-domains = <&power RK3588_PD_VDPU>;
		status = "disabled";
	};

	jpege3_mmu: iommu@fdbac800 {
		compatible = "rockchip,iommu-v2";
		reg = <0x0 0xfdbac800 0x0 0x40>;
		interrupts = <GIC_SPI 127 IRQ_TYPE_LEVEL_HIGH>;
		interrupt-names = "irq_jpege3_mmu";
		clocks = <&cru ACLK_JPEG_ENCODER3>, <&cru HCLK_JPEG_ENCODER3>;
		clock-names = "aclk", "iface";
		power-domains = <&power RK3588_PD_VDPU>;
		#iommu-cells = <0>;
		status = "disabled";
	};

	iep: iep@fdbb0000 {
		compatible = "rockchip,iep-v2";
		reg = <0x0 0xfdbb0000 0x0 0x500>;
		interrupts = <GIC_SPI 117 IRQ_TYPE_LEVEL_HIGH>;
		interrupt-names = "irq_iep";
		clocks = <&cru ACLK_IEP2P0>, <&cru HCLK_IEP2P0>, <&cru CLK_IEP2P0_CORE>;
		clock-names = "aclk", "hclk", "sclk";
		rockchip,normal-rates = <594000000>, <0>;
		assigned-clocks = <&cru ACLK_IEP2P0>;
		assigned-clock-rates = <594000000>;
		resets = <&cru SRST_A_IEP2P0>, <&cru SRST_H_IEP2P0>, <&cru SRST_IEP2P0_CORE>;
		reset-names = "rst_a", "rst_h", "rst_s";
		rockchip,skip-pmu-idle-request;
		rockchip,disable-auto-freq;
		power-domains = <&power RK3588_PD_VDPU>;
		rockchip,srv = <&mpp_srv>;
		rockchip,taskqueue-node = <6>;
		iommus = <&iep_mmu>;
		status = "disabled";
	};

	iep_mmu: iommu@fdbb0800 {
		compatible = "rockchip,iommu-v2";
		reg = <0x0 0xfdbb0800 0x0 0x100>;
		interrupts = <GIC_SPI 117 IRQ_TYPE_LEVEL_HIGH>;
		interrupt-names = "irq_iep_mmu";
		clocks = <&cru ACLK_IEP2P0>, <&cru HCLK_IEP2P0>;
		clock-names = "aclk", "iface";
		#iommu-cells = <0>;
		power-domains = <&power RK3588_PD_VDPU>;
		status = "disabled";
	};

	rkvenc0: rkvenc-core@fdbd0000 {
		compatible = "rockchip,rkv-encoder-v2-core";
		reg = <0x0 0xfdbd0000 0x0 0x6000>;
		interrupts = <GIC_SPI 101 IRQ_TYPE_LEVEL_HIGH>;
		interrupt-names = "irq_rkvenc0";
		clocks = <&cru ACLK_RKVENC0>, <&cru HCLK_RKVENC0>, <&cru CLK_RKVENC0_CORE>;
		clock-names = "aclk_vcodec", "hclk_vcodec", "clk_core";
		rockchip,normal-rates = <500000000>, <0>, <800000000>;
		assigned-clocks = <&cru ACLK_RKVENC0>, <&cru CLK_RKVENC0_CORE>;
		assigned-clock-rates = <500000000>, <800000000>;
		resets = <&cru SRST_A_RKVENC0>, <&cru SRST_H_RKVENC0>, <&cru SRST_RKVENC0_CORE>;
		reset-names = "video_a", "video_h", "video_core";
		rockchip,skip-pmu-idle-request;
		iommus = <&rkvenc0_mmu>;
		rockchip,srv = <&mpp_srv>;
		rockchip,ccu = <&rkvenc_ccu>;
		rockchip,taskqueue-node = <7>;
		rockchip,task-capacity = <8>;
		power-domains = <&power RK3588_PD_VENC0>;
		operating-points-v2 = <&venc_opp_table>;
		status = "disabled";
	};

	rkvenc0_mmu: iommu@fdbdf000 {
		compatible = "rockchip,iommu-v2";
		reg = <0x0 0xfdbdf000 0x0 0x40>, <0x0 0xfdbdf040 0x0 0x40>;
		interrupts = <GIC_SPI 99 IRQ_TYPE_LEVEL_HIGH>,
			     <GIC_SPI 100 IRQ_TYPE_LEVEL_HIGH>;
		interrupt-names = "irq_rkvenc0_mmu0", "irq_rkvenc0_mmu1";
		clocks = <&cru ACLK_RKVENC0>, <&cru HCLK_RKVENC0>;
		clock-names = "aclk", "iface";
		rockchip,disable-mmu-reset;
		rockchip,enable-cmd-retry;
		rockchip,shootdown-entire;
		#iommu-cells = <0>;
		power-domains = <&power RK3588_PD_VENC0>;
		status = "disabled";
	};

	rkvenc1: rkvenc-core@fdbe0000 {
		compatible = "rockchip,rkv-encoder-v2-core";
		reg = <0x0 0xfdbe0000 0x0 0x6000>;
		interrupts = <GIC_SPI 104 IRQ_TYPE_LEVEL_HIGH>;
		interrupt-names = "irq_rkvenc1";
		clocks = <&cru ACLK_RKVENC1>, <&cru HCLK_RKVENC1>, <&cru CLK_RKVENC1_CORE>;
		clock-names = "aclk_vcodec", "hclk_vcodec", "clk_core";
		rockchip,normal-rates = <500000000>, <0>, <800000000>;
		assigned-clocks = <&cru ACLK_RKVENC1>, <&cru CLK_RKVENC1_CORE>;
		assigned-clock-rates = <500000000>, <800000000>;
		resets = <&cru SRST_A_RKVENC1>, <&cru SRST_H_RKVENC1>, <&cru SRST_RKVENC1_CORE>;
		reset-names = "video_a", "video_h", "video_core";
		rockchip,skip-pmu-idle-request;
		iommus = <&rkvenc1_mmu>;
		rockchip,srv = <&mpp_srv>;
		rockchip,ccu = <&rkvenc_ccu>;
		rockchip,taskqueue-node = <7>;
		rockchip,task-capacity = <8>;
		power-domains = <&power RK3588_PD_VENC1>;
		operating-points-v2 = <&venc_opp_table>;
		status = "disabled";
	};

	rkvenc1_mmu: iommu@fdbef000 {
		compatible = "rockchip,iommu-v2";
		reg = <0x0 0xfdbef000 0x0 0x40>, <0x0 0xfdbef040 0x0 0x40>;
		interrupts = <GIC_SPI 102 IRQ_TYPE_LEVEL_HIGH>,
			     <GIC_SPI 103 IRQ_TYPE_LEVEL_HIGH>;
		interrupt-names = "irq_rkvenc1_mmu0", "irq_rkvenc1_mmu1";
		clocks = <&cru ACLK_RKVENC1>, <&cru HCLK_RKVENC1>;
		lock-names = "aclk", "iface";
		rockchip,disable-mmu-reset;
		rockchip,enable-cmd-retry;
		rockchip,shootdown-entire;
		#iommu-cells = <0>;
		power-domains = <&power RK3588_PD_VENC1>;
		status = "disabled";
	};

	venc_opp_table: venc-opp-table {
		compatible = "operating-points-v2";

		nvmem-cells = <&codec_leakage>, <&venc_opp_info>;
		nvmem-cell-names = "leakage", "opp-info";
		rockchip,leakage-voltage-sel = <
			1	15	0
			16	25	1
			26	254	2
		>;

		rockchip,grf = <&sys_grf>;
		volt-mem-read-margin = <
			855000	1
			765000	2
			675000	3
			495000	4
		>;

		opp-800000000 {
			opp-hz = /bits/ 64 <800000000>;
			opp-microvolt = <750000 750000 850000>,
					<750000 750000 850000>;
			opp-microvolt-L0 = <800000 800000 850000>,
					   <800000 800000 850000>;
			opp-microvolt-L1 = <775000 775000 850000>,
					   <775000 775000 850000>;
			opp-microvolt-L2 = <750000 750000 850000>,
					   <750000 750000 850000>;
		};
	};

	rkvdec_ccu: rkvdec-ccu@fdc30000 {
		compatible = "rockchip,rkv-decoder-v2-ccu";
		reg = <0x0 0xfdc30000 0x0 0x100>;
		reg-names = "ccu";
		clocks = <&cru ACLK_RKVDEC_CCU>;
		clock-names = "aclk_ccu";
		assigned-clocks = <&cru ACLK_RKVDEC_CCU>;
		assigned-clock-rates = <600000000>;
		resets = <&cru SRST_A_RKVDEC_CCU>;
		reset-names = "video_ccu";
		rockchip,skip-pmu-idle-request;
		/* 1: soft ccu 2: hw ccu */
		rockchip,ccu-mode = <1>;
		power-domains = <&power RK3588_PD_RKVDEC0>;
		status = "disabled";
	};

	rkvdec0: rkvdec-core@fdc38000 {
		compatible = "rockchip,rkv-decoder-v2";
		reg = <0x0 0xfdc38100 0x0 0x400>, <0x0 0xfdc38000 0x0 0x100>;
		reg-names = "regs", "link";
		interrupts = <GIC_SPI 95 IRQ_TYPE_LEVEL_HIGH>;
		interrupt-names = "irq_rkvdec0";
		clocks = <&cru ACLK_RKVDEC0>, <&cru HCLK_RKVDEC0>, <&cru CLK_RKVDEC0_CORE>,
			 <&cru CLK_RKVDEC0_CA>, <&cru CLK_RKVDEC0_HEVC_CA>;
		clock-names = "aclk_vcodec", "hclk_vcodec", "clk_core",
			      "clk_cabac", "clk_hevc_cabac";
		rockchip,normal-rates = <800000000>, <0>, <600000000>,
					<600000000>, <1000000000>;
		assigned-clocks = <&cru ACLK_RKVDEC0>, <&cru CLK_RKVDEC0_CORE>,
				  <&cru CLK_RKVDEC0_CA>, <&cru CLK_RKVDEC0_HEVC_CA>;
		assigned-clock-rates = <800000000>, <600000000>,
				       <600000000>, <1000000000>;
		resets = <&cru SRST_A_RKVDEC0>, <&cru SRST_H_RKVDEC0>, <&cru SRST_RKVDEC0_CORE>,
			 <&cru SRST_RKVDEC0_CA>, <&cru SRST_RKVDEC0_HEVC_CA>;
		reset-names = "video_a", "video_h", "video_core",
			      "video_cabac", "video_hevc_cabac";
		rockchip,skip-pmu-idle-request;
		iommus = <&rkvdec0_mmu>;
		rockchip,srv = <&mpp_srv>;
		rockchip,ccu = <&rkvdec_ccu>;
		rockchip,core-mask = <0x00010001>;
		rockchip,task-capacity = <16>;
		rockchip,taskqueue-node = <9>;
		rockchip,sram = <&rkvdec0_sram>;
		/* rcb_iova: start and size 1M@4095M */
		rockchip,rcb-iova = <0xFFF00000 0x100000>;
		rockchip,rcb-info = <136 24576>, <137 49152>, <141 90112>, <140 49152>,
				    <139 180224>, <133 49152>, <134 8192>, <135 4352>,
				    <138 13056>, <142 291584>;
		rockchip,rcb-min-width = <512>;
		power-domains = <&power RK3588_PD_RKVDEC0>;
		status = "disabled";
	};

	rkvdec0_mmu: iommu@fdc38700 {
		compatible = "rockchip,iommu-v2";
		reg = <0x0 0xfdc38700 0x0 0x40>, <0x0 0xfdc38740 0x0 0x40>;
		interrupts = <GIC_SPI 96 IRQ_TYPE_LEVEL_HIGH>;
		interrupt-names = "irq_rkvdec0_mmu";
		clocks = <&cru ACLK_RKVDEC0>, <&cru HCLK_RKVDEC0>;
		clock-names = "aclk", "iface";
		rockchip,disable-mmu-reset;
		rockchip,enable-cmd-retry;
		rockchip,shootdown-entire;
		rockchip,master-handle-irq;
		#iommu-cells = <0>;
		power-domains = <&power RK3588_PD_RKVDEC0>;
		status = "disabled";
	};

	rkvdec1: rkvdec-core@fdc48000 {
		compatible = "rockchip,rkv-decoder-v2";
		reg = <0x0 0xfdc48100 0x0 0x400>, <0x0 0xfdc48000 0x0 0x100>;
		reg-names = "regs", "link";
		interrupts = <GIC_SPI 97 IRQ_TYPE_LEVEL_HIGH>;
		interrupt-names = "irq_rkvdec1";
		clocks = <&cru ACLK_RKVDEC1>, <&cru HCLK_RKVDEC1>, <&cru CLK_RKVDEC1_CORE>,
			 <&cru CLK_RKVDEC1_CA>, <&cru CLK_RKVDEC1_HEVC_CA>;
		clock-names = "aclk_vcodec", "hclk_vcodec", "clk_core",
			      "clk_cabac", "clk_hevc_cabac";
		rockchip,normal-rates = <800000000>, <0>, <600000000>,
					<600000000>, <1000000000>;
		assigned-clocks = <&cru ACLK_RKVDEC1>, <&cru CLK_RKVDEC1_CORE>,
				  <&cru CLK_RKVDEC1_CA>, <&cru CLK_RKVDEC1_HEVC_CA>;
		assigned-clock-rates = <800000000>, <600000000>,
				       <600000000>, <1000000000>;
		resets = <&cru SRST_A_RKVDEC1>, <&cru SRST_H_RKVDEC1>, <&cru SRST_RKVDEC1_CORE>,
			 <&cru SRST_RKVDEC1_CA>, <&cru SRST_RKVDEC1_HEVC_CA>;
		reset-names = "video_a", "video_h", "video_core",
			      "video_cabac", "video_hevc_cabac";
		rockchip,skip-pmu-idle-request;
		iommus = <&rkvdec1_mmu>;
		rockchip,srv = <&mpp_srv>;
		rockchip,ccu = <&rkvdec_ccu>;
		rockchip,core-mask = <0x00020002>;
		rockchip,task-capacity = <16>;
		rockchip,taskqueue-node = <9>;
		rockchip,sram = <&rkvdec1_sram>;
		/* rcb_iova: start and size 1M@4094M */
		rockchip,rcb-iova = <0xFFE00000 0x100000>;
		rockchip,rcb-info = <136 24576>, <137 49152>, <141 90112>, <140 49152>,
				    <139 180224>, <133 49152>, <134 8192>, <135 4352>,
				    <138 13056>, <142 291584>;
		rockchip,rcb-min-width = <512>;
		power-domains = <&power RK3588_PD_RKVDEC1>;
		status = "disabled";
	};

	rkvdec1_mmu: iommu@fdc48700 {
		compatible = "rockchip,iommu-v2";
		reg = <0x0 0xfdc48700 0x0 0x40>, <0x0 0xfdc48740 0x0 0x40>;
		interrupts = <GIC_SPI 98 IRQ_TYPE_LEVEL_HIGH>;
		interrupt-names = "irq_rkvdec1_mmu";
		clocks = <&cru ACLK_RKVDEC1>, <&cru HCLK_RKVDEC1>;
		clock-names = "aclk", "iface";
		rockchip,disable-mmu-reset;
		rockchip,enable-cmd-retry;
		rockchip,shootdown-entire;
		rockchip,master-handle-irq;
		#iommu-cells = <0>;
		power-domains = <&power RK3588_PD_RKVDEC1>;
		status = "disabled";
	};

	av1d_mmu: iommu@fdca0000 {
		compatible = "rockchip,iommu-av1d";
		reg = <0x0 0xfdca0000 0x0 0x600>;
		interrupts = <GIC_SPI 109 IRQ_TYPE_LEVEL_HIGH>;
		interrupt-names = "irq_av1d_mmu";
		clocks = <&cru ACLK_AV1>, <&cru PCLK_AV1>;
		clock-names = "aclk", "iface";
		#iommu-cells = <0>;
		power-domains = <&power RK3588_PD_AV1>;
		status = "disabled";
	};

	rkcif: rkcif@fdce0000 {
		compatible = "rockchip,rk3588-cif";
		reg = <0x0 0xfdce0000 0x0 0x800>;
		reg-names = "cif_regs";
		interrupts = <GIC_SPI 155 IRQ_TYPE_LEVEL_HIGH>;
		interrupt-names = "cif-intr";
		clocks = <&cru ACLK_VICAP>, <&cru HCLK_VICAP>, <&cru DCLK_VICAP>,
			 <&cru ICLK_CSIHOST0>, <&cru ICLK_CSIHOST1>;
		clock-names = "aclk_cif", "hclk_cif", "dclk_cif",
			      "iclk_host0", "iclk_host1";
		resets = <&cru SRST_A_VICAP>, <&cru SRST_H_VICAP>, <&cru SRST_D_VICAP>,
			 <&cru SRST_CSIHOST0_VICAP>, <&cru SRST_CSIHOST1_VICAP>,
			 <&cru SRST_CSIHOST2_VICAP>, <&cru SRST_CSIHOST3_VICAP>,
			 <&cru SRST_CSIHOST4_VICAP>, <&cru SRST_CSIHOST5_VICAP>;
		reset-names = "rst_cif_a", "rst_cif_h", "rst_cif_d",
			      "rst_cif_host0", "rst_cif_host1", "rst_cif_host2",
			      "rst_cif_host3", "rst_cif_host4", "rst_cif_host5";
		assigned-clocks = <&cru DCLK_VICAP>;
		assigned-clock-rates = <600000000>;
		power-domains = <&power RK3588_PD_VI>;
		rockchip,grf = <&sys_grf>;
		iommus = <&rkcif_mmu>;
		nvmem-cells = <&specification_serial_number>,
			      <&package_serial_number_low>,
			      <&package_serial_number_high>;
		nvmem-cell-names = "specification",
				   "package_low",
				   "package_high";
		status = "disabled";
	};

	rkcif_mmu: iommu@fdce0800 {
		compatible = "rockchip,iommu-v2";
		reg = <0x0 0xfdce0800 0x0 0x100>,
		      <0x0 0xfdce0900 0x0 0x100>;
		interrupts = <GIC_SPI 113 IRQ_TYPE_LEVEL_HIGH>;
		interrupt-names = "cif_mmu";
		clocks = <&cru ACLK_VICAP>, <&cru HCLK_VICAP>;
		clock-names = "aclk", "iface";
		power-domains = <&power RK3588_PD_VI>;
		rockchip,disable-mmu-reset;
		#iommu-cells = <0>;
		status = "disabled";
	};

	vop: vop@fdd90000 {
		compatible = "rockchip,rk3588-vop";
		reg = <0x0 0xfdd90000 0x0 0x4200>, <0x0 0xfdd95000 0x0 0x1000>;
		reg-names = "regs", "gamma_lut";
		interrupts = <GIC_SPI 156 IRQ_TYPE_LEVEL_HIGH>;
		clocks = <&cru ACLK_VOP>,
			 <&cru HCLK_VOP>,
			 <&cru DCLK_VOP0>,
			 <&cru DCLK_VOP1>,
			 <&cru DCLK_VOP2>,
			 <&cru DCLK_VOP3>,
			 <&cru PCLK_VOP_ROOT>,
			 <&cru DCLK_VOP0_SRC>,
			 <&cru DCLK_VOP1_SRC>,
			 <&cru DCLK_VOP2_SRC>;
		clock-names = "aclk_vop",
			      "hclk_vop",
			      "dclk_vp0",
			      "dclk_vp1",
			      "dclk_vp2",
			      "dclk_vp3",
			      "pclk_vop",
			      "dclk_src_vp0",
			      "dclk_src_vp1",
			      "dclk_src_vp2";
		assigned-clocks = <&cru ACLK_VOP>;
		assigned-clock-rates = <750000000>;
		resets = <&cru SRST_A_VOP>,
			 <&cru SRST_H_VOP>,
			 <&cru SRST_D_VOP0>,
			 <&cru SRST_D_VOP1>,
			 <&cru SRST_D_VOP2>,
			 <&cru SRST_D_VOP3>;
		reset-names = "axi",
			      "ahb",
			      "dclk_vp0",
			      "dclk_vp1",
			      "dclk_vp2",
			      "dclk_vp3";
		rockchip,aclk-normal-mode-rates = <500000000>;
		rockchip,aclk-advanced-mode-rates = <750000000>;
		operating-points-v2 = <&vop_opp_table>;
		iommus = <&vop_mmu>;
		power-domains = <&power RK3588_PD_VOP>;
		rockchip,grf = <&sys_grf>;
		rockchip,vop-grf = <&vop_grf>;
		rockchip,vo1-grf = <&vo1_grf>;
		rockchip,pmu = <&pmu>;

		status = "disabled";

		vop_out: ports {
			#address-cells = <1>;
			#size-cells = <0>;

			vp0: port@0 {
				#address-cells = <1>;
				#size-cells = <0>;
				reg = <0>;

				vp0_out_dp0: endpoint@0 {
					reg = <0>;
					remote-endpoint = <&dp0_in_vp0>;
				};

				vp0_out_edp0: endpoint@1 {
					reg = <1>;
					remote-endpoint = <&edp0_in_vp0>;
				};

				vp0_out_hdmi0: endpoint@2 {
					reg = <2>;
					remote-endpoint = <&hdmi0_in_vp0>;
				};
			};

			vp1: port@1 {
				#address-cells = <1>;
				#size-cells = <0>;
				reg = <1>;

				vp1_out_dp0: endpoint@0 {
					reg = <0>;
					remote-endpoint = <&dp0_in_vp1>;
				};

				vp1_out_edp0: endpoint@1 {
					reg = <1>;
					remote-endpoint = <&edp0_in_vp1>;
				};

				vp1_out_hdmi0: endpoint@2 {
					reg = <2>;
					remote-endpoint = <&hdmi0_in_vp1>;
				};
			};

			vp2: port@2 {
				#address-cells = <1>;
				#size-cells = <0>;
				reg = <2>;

				assigned-clocks = <&cru DCLK_VOP2_SRC>;
				assigned-clock-parents = <&cru PLL_V0PLL>;

				vp2_out_dp0: endpoint@0 {
					reg = <0>;
					remote-endpoint = <&dp0_in_vp2>;
				};

				vp2_out_edp0: endpoint@1 {
					reg = <1>;
					remote-endpoint = <&edp0_in_vp2>;
				};

				vp2_out_hdmi0: endpoint@2 {
					reg = <2>;
					remote-endpoint = <&hdmi0_in_vp2>;
				};

				vp2_out_dsi0: endpoint@3 {
					reg = <3>;
					remote-endpoint = <&dsi0_in_vp2>;
				};

				vp2_out_dsi1: endpoint@4 {
					reg = <4>;
					remote-endpoint = <&dsi1_in_vp2>;
				};
			};

			vp3: port@3 {
				#address-cells = <1>;
				#size-cells = <0>;
				reg = <3>;

				vp3_out_dsi0: endpoint@0 {
					reg = <0>;
					remote-endpoint = <&dsi0_in_vp3>;
				};

				vp3_out_dsi1: endpoint@1 {
					reg = <1>;
					remote-endpoint = <&dsi1_in_vp3>;
				};

				vp3_out_rgb: endpoint@2 {
					reg = <2>;
					remote-endpoint = <&rgb_in_vp3>;
				};
			};
		};
	};

	vop_opp_table: vop-opp-table {
		compatible = "operating-points-v2";

		nvmem-cells = <&log_leakage>;
		nvmem-cell-names = "leakage";

		rockchip,init-freq = <750000>; /* KHz */

		rockchip,leakage-voltage-sel = <
			1	31	0
			32	44	1
			45	57	2
			58	254	3
		>;

		opp-5000000000 {
			opp-hz = /bits/ 64 <500000000>;
			opp-microvolt = <725000 725000 800000>;
			opp-microvolt-L1 = <700000 700000 800000>;
			opp-microvolt-L2 = <687500 687500 800000>;
			opp-microvolt-L3 = <675000 675000 800000>;
		};
		opp-7500000000 {
			opp-hz = /bits/ 64 <750000000>;
			opp-microvolt = <725000 725000 800000>;
			opp-microvolt-L1 = <700000 700000 800000>;
			opp-microvolt-L2 = <687500 687500 800000>;
			opp-microvolt-L3 = <675000 675000 800000>;
		};
		opp-8500000000 {
			opp-hz = /bits/ 64 <850000000>;
			opp-microvolt = <800000 800000 800000>;
			opp-microvolt-L1 = <775000 775000 800000>;
			opp-microvolt-L2 = <750000 750000 800000>;
			opp-microvolt-L3 = <750000 750000 800000>;
		};
	};

	spdif_tx2: spdif-tx@fddb0000 {
		compatible = "rockchip,rk3588-spdif", "rockchip,rk3568-spdif";
		reg = <0x0 0xfddb0000 0x0 0x1000>;
		interrupts = <GIC_SPI 195 IRQ_TYPE_LEVEL_HIGH>;
		dmas = <&dmac1 6>;
		dma-names = "tx";
		clock-names = "mclk", "hclk";
		clocks = <&cru MCLK_SPDIF2>, <&cru HCLK_SPDIF2_DP0>;
		assigned-clocks = <&cru CLK_SPDIF2_DP0_SRC>;
		assigned-clock-parents = <&cru PLL_AUPLL>;
		power-domains = <&power RK3588_PD_VO0>;
		#sound-dai-cells = <0>;
		status = "disabled";
	};

	dsi0: dsi@fde20000 {
		compatible = "rockchip,rk3588-mipi-dsi2";
		reg = <0x0 0xfde20000 0x0 0x10000>;
		interrupts = <GIC_SPI 167 IRQ_TYPE_LEVEL_HIGH>;
		clocks = <&cru PCLK_DSIHOST0>, <&cru CLK_DSIHOST0>;
		clock-names = "pclk", "sys_clk";
		resets = <&cru SRST_P_DSIHOST0>;
		reset-names = "apb";
		power-domains = <&power RK3588_PD_VOP>;
		phys = <&mipidcphy0>;
		phy-names = "dcphy";
		rockchip,grf = <&vop_grf>;
		#address-cells = <1>;
		#size-cells = <0>;
		status = "disabled";

		ports {
			#address-cells = <1>;
			#size-cells = <0>;

			dsi0_in: port@0 {
				reg = <0>;
				#address-cells = <1>;
				#size-cells = <0>;

				dsi0_in_vp2: endpoint@0 {
					reg = <0>;
					remote-endpoint = <&vp2_out_dsi0>;
					status = "disabled";
				};

				dsi0_in_vp3: endpoint@1 {
					reg = <1>;
					remote-endpoint = <&vp3_out_dsi0>;
					status = "disabled";
				};
			};
		};
	};

	dsi1: dsi@fde30000 {
		compatible = "rockchip,rk3588-mipi-dsi2";
		reg = <0x0 0xfde30000 0x0 0x10000>;
		interrupts = <GIC_SPI 168 IRQ_TYPE_LEVEL_HIGH>;
		clocks = <&cru PCLK_DSIHOST1>, <&cru CLK_DSIHOST1>;
		clock-names = "pclk", "sys_clk";
		resets = <&cru SRST_P_DSIHOST1>;
		reset-names = "apb";
		power-domains = <&power RK3588_PD_VOP>;
		phys = <&mipidcphy1>;
		phy-names = "dcphy";
		rockchip,grf = <&vop_grf>;
		#address-cells = <1>;
		#size-cells = <0>;
		status = "disabled";

		ports {
			#address-cells = <1>;
			#size-cells = <0>;

			dsi1_in: port@0 {
				reg = <0>;
				#address-cells = <1>;
				#size-cells = <0>;

				dsi1_in_vp2: endpoint@0 {
					reg = <0>;
					remote-endpoint = <&vp2_out_dsi1>;
					status = "disabled";
				};

				dsi1_in_vp3: endpoint@1 {
					reg = <1>;
					remote-endpoint = <&vp3_out_dsi1>;
					status = "disabled";
				};
			};
		};
	};

	dp0: dp@fde50000 {
		compatible = "rockchip,rk3588-dp";
		reg = <0x0 0xfde50000 0x0 0x4000>;
		interrupts = <GIC_SPI 161 IRQ_TYPE_LEVEL_HIGH>;
		clocks = <&cru PCLK_DP0>, <&cru CLK_AUX16M_0>,
			 <&cru MCLK_I2S4_8CH_TX>, <&cru MCLK_SPDIF2_DP0>,
			 <&hclk_vo0>, <&cru CLK_DP0>;
		clock-names = "apb", "aux", "i2s", "spdif", "hclk", "hdcp";
		assigned-clocks = <&cru CLK_AUX16M_0>;
		assigned-clock-rates = <16000000>;
		resets = <&cru SRST_DP0>;
		phys = <&usbdp_phy0_dp>;
		power-domains = <&power RK3588_PD_VO0>;
		#sound-dai-cells = <1>;
		status = "disabled";

		ports {
			#address-cells = <1>;
			#size-cells = <0>;

			port@0 {
				reg = <0>;
				#address-cells = <1>;
				#size-cells = <0>;

				dp0_in_vp0: endpoint@0 {
					reg = <0>;
					remote-endpoint = <&vp0_out_dp0>;
					status = "disabled";
				};

				dp0_in_vp1: endpoint@1 {
					reg = <1>;
					remote-endpoint = <&vp1_out_dp0>;
					status = "disabled";
				};

				dp0_in_vp2: endpoint@2 {
					reg = <2>;
					remote-endpoint = <&vp2_out_dp0>;
					status = "disabled";
				};
			};

			port@1 {
				reg = <1>;

				dp0_out: endpoint { };
			};
		};
	};

	hdmi0: hdmi@fde80000 {
		compatible = "rockchip,rk3588-dw-hdmi";
		reg = <0x0 0xfde80000 0x0 0x10000>, <0x0 0xfde90000 0x0 0x10000>;
		interrupts = <GIC_SPI 169 IRQ_TYPE_LEVEL_HIGH>,
			     <GIC_SPI 170 IRQ_TYPE_LEVEL_HIGH>,
			     <GIC_SPI 171 IRQ_TYPE_LEVEL_HIGH>,
			     <GIC_SPI 172 IRQ_TYPE_LEVEL_HIGH>,
			     <GIC_SPI 360 IRQ_TYPE_LEVEL_HIGH>;
		clocks = <&cru PCLK_HDMITX0>,
			 <&cru CLK_HDMIHDP0>,
			 <&cru CLK_HDMITX0_EARC>,
			 <&cru CLK_HDMITX0_REF>,
			 <&cru MCLK_I2S5_8CH_TX>,
			 <&cru DCLK_VOP0>,
			 <&cru DCLK_VOP1>,
			 <&cru DCLK_VOP2>,
			 <&cru DCLK_VOP3>,
			 <&hclk_vo1>,
			 <&hdptxphy_hdmi0>;
		clock-names = "pclk",
			      "hpd",
			      "earc",
			      "hdmitx_ref",
			      "aud",
			      "dclk_vp0",
			      "dclk_vp1",
			      "dclk_vp2",
			      "dclk_vp3",
			      "hclk_vo1",
			      "link_clk";
		resets = <&cru SRST_HDMITX0_REF>, <&cru SRST_HDMIHDP0>;
		reset-names = "ref", "hdp";
		power-domains = <&power RK3588_PD_VO1>;
		pinctrl-names = "default";
		pinctrl-0 = <&hdmim0_tx0_cec &hdmim0_tx0_hpd &hdmim0_tx0_scl &hdmim0_tx0_sda>;
		reg-io-width = <4>;
		rockchip,grf = <&sys_grf>;
		rockchip,vo1_grf = <&vo1_grf>;
		phys = <&hdptxphy_hdmi0>;
		phy-names = "hdmi";
		#sound-dai-cells = <0>;
		status = "disabled";

		ports {
			#address-cells = <1>;
			#size-cells = <0>;

			hdmi0_in: port@0 {
				reg = <0>;
				#address-cells = <1>;
				#size-cells = <0>;

				hdmi0_in_vp0: endpoint@0 {
					reg = <0>;
					remote-endpoint = <&vp0_out_hdmi0>;
					status = "disabled";
				};

				hdmi0_in_vp1: endpoint@1 {
					reg = <1>;
					remote-endpoint = <&vp1_out_hdmi0>;
					status = "disabled";
				};

				hdmi0_in_vp2: endpoint@2 {
					reg = <2>;
					remote-endpoint = <&vp2_out_hdmi0>;
					status = "disabled";
				};
			};
		};
	};

	edp0: edp@fdec0000 {
		compatible = "rockchip,rk3588-edp";
		reg = <0x0 0xfdec0000 0x0 0x1000>;
		interrupts = <GIC_SPI 163 IRQ_TYPE_LEVEL_HIGH>;
		clocks = <&cru CLK_EDP0_24M>, <&cru PCLK_EDP0>,
			 <&cru CLK_EDP0_200M>, <&hclk_vo1>;
		clock-names = "dp", "pclk", "spdif", "hclk";
		resets = <&cru SRST_EDP0_24M>, <&cru SRST_P_EDP0>;
		reset-names = "dp", "apb";
		phys = <&hdptxphy0>;
		phy-names = "dp";
		power-domains = <&power RK3588_PD_VO1>;
		rockchip,grf = <&vo1_grf>;
		#sound-dai-cells = <1>;
		status = "disabled";

		ports {
			#address-cells = <1>;
			#size-cells = <0>;

			port@0 {
				reg = <0>;
				#address-cells = <1>;
				#size-cells = <0>;

				edp0_in_vp0: endpoint@0 {
					reg = <0>;
					remote-endpoint = <&vp0_out_edp0>;
					status = "disabled";
				};

				edp0_in_vp1: endpoint@1 {
					reg = <1>;
					remote-endpoint = <&vp1_out_edp0>;
					status = "disabled";
				};

				edp0_in_vp2: endpoint@2 {
					reg = <2>;
					remote-endpoint = <&vp2_out_edp0>;
					status = "disabled";
				};
			};

			port@1 {
				reg = <1>;

				edp0_out: endpoint { };
			};
		};
	};

	rng: rng@fe378000 {
		compatible = "rockchip,trngv1";
		reg = <0x0 0xfe378000 0x0 0x200>;
		interrupts = <GIC_SPI 400 IRQ_TYPE_LEVEL_HIGH>;
		clocks = <&scmi_clk SCMI_HCLK_SECURE_NS>;
		clock-names = "hclk_trng";
		resets = <&scmi_reset SRST_H_TRNG_NS>;
		reset-names = "reset";
		status = "disabled";
	};

	hdptxphy0: phy@fed60000 {
		compatible = "rockchip,rk3588-hdptx-phy";
		reg = <0x0 0xfed60000 0x0 0x2000>;
		clocks = <&cru CLK_USB2PHY_HDPTXRXPHY_REF>, <&cru PCLK_HDPTX0>;
		clock-names = "ref", "apb";
		resets = <&cru SRST_P_HDPTX0>, <&cru SRST_HDPTX0_INIT>,
			 <&cru SRST_HDPTX0_CMN>, <&cru SRST_HDPTX0_LANE>;
		reset-names = "apb", "init", "cmn", "lane";
		rockchip,grf = <&hdptxphy0_grf>;
		#phy-cells = <0>;
		status = "disabled";
	};

	usbdp_phy0: phy@fed80000 {
		compatible = "rockchip,rk3588-usbdp-phy";
		reg = <0x0 0xfed80000 0x0 0x10000>;
		rockchip,u2phy-grf = <&usb2phy0_grf>;
		rockchip,usb-grf = <&usb_grf>;
		rockchip,usbdpphy-grf = <&usbdpphy0_grf>;
		rockchip,vo-grf = <&vo0_grf>;
		clocks = <&cru CLK_USBDPPHY_MIPIDCPPHY_REF>,
			 <&cru CLK_USBDP_PHY0_IMMORTAL>,
			 <&cru PCLK_USBDPPHY0>,
			 <&u2phy0>;
		clock-names = "refclk", "immortal", "pclk", "utmi";
		resets = <&cru SRST_USBDP_COMBO_PHY0_INIT>,
			 <&cru SRST_USBDP_COMBO_PHY0_CMN>,
			 <&cru SRST_USBDP_COMBO_PHY0_LANE>,
			 <&cru SRST_USBDP_COMBO_PHY0_PCS>,
			 <&cru SRST_P_USBDPPHY0>;
		reset-names = "init", "cmn", "lane", "pcs_apb", "pma_apb";
		status = "disabled";

		usbdp_phy0_dp: dp-port {
			#phy-cells = <0>;
			status = "disabled";
		};

		usbdp_phy0_u3: u3-port {
			#phy-cells = <0>;
			status = "disabled";
		};
	};

	mipidcphy0: phy@feda0000 {
		compatible = "rockchip,rk3588-mipi-dcphy";
		reg = <0x0 0xfeda0000 0x0 0x10000>;
		rockchip,grf = <&mipidcphy0_grf>;
		clocks = <&cru PCLK_MIPI_DCPHY0>,
			 <&cru CLK_USBDPPHY_MIPIDCPPHY_REF>;
		clock-names = "pclk", "ref";
		resets = <&cru SRST_M_MIPI_DCPHY0>,
			 <&cru SRST_P_MIPI_DCPHY0>,
			 <&cru SRST_P_MIPI_DCPHY0_GRF>,
			 <&cru SRST_S_MIPI_DCPHY0>;
		reset-names = "m_phy", "apb", "grf", "s_phy";
		#phy-cells = <0>;
		status = "okay";
	};

	mipidcphy1: phy@fedb0000 {
		compatible = "rockchip,rk3588-mipi-dcphy";
		reg = <0x0 0xfedb0000 0x0 0x10000>;
		rockchip,grf = <&mipidcphy1_grf>;
		clocks = <&cru PCLK_MIPI_DCPHY1>,
			 <&cru CLK_USBDPPHY_MIPIDCPPHY_REF>;
		clock-names = "pclk", "ref";
		resets = <&cru SRST_M_MIPI_DCPHY1>,
			 <&cru SRST_P_MIPI_DCPHY1>,
			 <&cru SRST_P_MIPI_DCPHY1_GRF>,
			 <&cru SRST_S_MIPI_DCPHY1>;
		reset-names = "m_phy", "apb", "grf", "s_phy";
		#phy-cells = <0>;
		status = "okay";
	};

	syssram: sram@ff001000 {
		compatible = "mmio-sram";
		reg = <0x0 0xff001000 0x0 0xef000>;

		#address-cells = <1>;
		#size-cells = <1>;
		ranges = <0x0 0x0 0xff001000 0xef000>;
		/* start address and size should be 4k algin */
		rkvdec0_sram: rkvdec-sram@0 {
			reg = <0x0 0x78000>;
		};
		rkvdec1_sram: rkvdec-sram@78000 {
			reg = <0x78000 0x77000>;
		};
	};


	rkcif_mipi_lvds4: rkcif-mipi-lvds4 {
		compatible = "rockchip,rkcif-mipi-lvds";
		rockchip,hw = <&rkcif>;
		iommus = <&rkcif_mmu>;
		status = "disabled";
	};

	rkcif_mipi_lvds4_sditf: rkcif-mipi-lvds4-sditf {
		compatible = "rockchip,rkcif-sditf";
		rockchip,cif = <&rkcif_mipi_lvds4>;
		status = "disabled";
	};

	rkcif_mipi_lvds4_sditf_vir1: rkcif-mipi-lvds4-sditf-vir1 {
		compatible = "rockchip,rkcif-sditf";
		rockchip,cif = <&rkcif_mipi_lvds4>;
		status = "disabled";
	};

	rkcif_mipi_lvds4_sditf_vir2: rkcif-mipi-lvds4-sditf-vir2 {
		compatible = "rockchip,rkcif-sditf";
		rockchip,cif = <&rkcif_mipi_lvds4>;
		status = "disabled";
	};

	rkcif_mipi_lvds4_sditf_vir3: rkcif-mipi-lvds4-sditf-vir3 {
		compatible = "rockchip,rkcif-sditf";
		rockchip,cif = <&rkcif_mipi_lvds4>;
		status = "disabled";
	};

	rkcif_mipi_lvds5: rkcif-mipi-lvds5 {
		compatible = "rockchip,rkcif-mipi-lvds";
		rockchip,hw = <&rkcif>;
		iommus = <&rkcif_mmu>;
		status = "disabled";
	};

	rkcif_mipi_lvds5_sditf: rkcif-mipi-lvds5-sditf {
		compatible = "rockchip,rkcif-sditf";
		rockchip,cif = <&rkcif_mipi_lvds5>;
		status = "disabled";
	};

	rkcif_mipi_lvds5_sditf_vir1: rkcif-mipi-lvds5-sditf-vir1 {
		compatible = "rockchip,rkcif-sditf";
		rockchip,cif = <&rkcif_mipi_lvds5>;
		status = "disabled";
	};

	rkcif_mipi_lvds5_sditf_vir2: rkcif-mipi-lvds5-sditf-vir2 {
		compatible = "rockchip,rkcif-sditf";
		rockchip,cif = <&rkcif_mipi_lvds5>;
		status = "disabled";
	};

	rkcif_mipi_lvds5_sditf_vir3: rkcif-mipi-lvds5-sditf-vir3 {
		compatible = "rockchip,rkcif-sditf";
		rockchip,cif = <&rkcif_mipi_lvds5>;
		status = "disabled";
	};

	usbdrd3_1: usbdrd3_1 {
		compatible = "rockchip,rk3588-dwc3", "rockchip,rk3399-dwc3";
		clocks = <&cru REF_CLK_USB3OTG1>, <&cru SUSPEND_CLK_USB3OTG1>,
			 <&cru ACLK_USB3OTG1>;
		clock-names = "ref", "suspend", "bus";
		#address-cells = <2>;
		#size-cells = <2>;
		ranges;
		status = "disabled";

		usbdrd_dwc3_1: usb@fc400000 {
			compatible = "snps,dwc3";
			reg = <0x0 0xfc400000 0x0 0x400000>;
			interrupts = <GIC_SPI 221 IRQ_TYPE_LEVEL_HIGH>;
			power-domains = <&power RK3588_PD_USB>;
			resets = <&cru SRST_A_USB3OTG1>;
			reset-names = "usb3-otg";
			dr_mode = "host";
			phys = <&u2phy1_otg>, <&usbdp_phy1_u3>;
			phy-names = "usb2-phy", "usb3-phy";
			phy_type = "utmi_wide";
			snps,dis_enblslpm_quirk;
			snps,dis-u1-entry-quirk;
			snps,dis-u2-entry-quirk;
			snps,dis-u2-freeclk-exists-quirk;
			snps,dis-del-phy-power-chg-quirk;
			snps,dis-tx-ipgap-linecheck-quirk;
			snps,parkmode-disable-hs-quirk;
			snps,parkmode-disable-ss-quirk;
			status = "disabled";
		};
	};

	hdptxphy1_grf: syscon@fd5e4000 {
		compatible = "rockchip,rk3588-hdptxphy-grf", "syscon";
		reg = <0x0 0xfd5e4000 0x0 0x100>;
	};

	dp1: dp@fde60000 {
		compatible = "rockchip,rk3588-dp";
		reg = <0x0 0xfde60000 0x0 0x4000>;
		interrupts = <GIC_SPI 162 IRQ_TYPE_LEVEL_HIGH>;
		clocks = <&cru PCLK_DP1>, <&cru CLK_AUX16M_1>,
			 <&cru MCLK_I2S8_8CH_TX>, <&cru MCLK_SPDIF5_DP1>,
			 <&hclk_vo0>, <&cru CLK_DP1>;
		clock-names = "apb", "aux", "i2s", "spdif", "hclk", "hdcp";
		assigned-clocks = <&cru CLK_AUX16M_1>;
		assigned-clock-rates = <16000000>;
		resets = <&cru SRST_DP1>;
		phys = <&usbdp_phy1_dp>;
		power-domains = <&power RK3588_PD_VO0>;
		#sound-dai-cells = <1>;
		status = "disabled";

		ports {
			#address-cells = <1>;
			#size-cells = <0>;

			port@0 {
				reg = <0>;
				#address-cells = <1>;
				#size-cells = <0>;

				dp1_in_vp0: endpoint@0 {
					reg = <0>;
					remote-endpoint = <&vp0_out_dp1>;
					status = "disabled";
				};

				dp1_in_vp1: endpoint@1 {
					reg = <1>;
					remote-endpoint = <&vp1_out_dp1>;
					status = "disabled";
				};

				dp1_in_vp2: endpoint@2 {
					reg = <2>;
					remote-endpoint = <&vp2_out_dp1>;
					status = "disabled";
				};
			};

			port@1 {
				reg = <1>;

				dp1_out: endpoint { };
			};
		};
	};

	hdmi1: hdmi@fdea0000 {
		compatible = "rockchip,rk3588-dw-hdmi";
		reg = <0x0 0xfdea0000 0x0 0x10000>, <0x0 0xfdeb0000 0x0 0x10000>;
		interrupts = <GIC_SPI 173 IRQ_TYPE_LEVEL_HIGH>,
			     <GIC_SPI 174 IRQ_TYPE_LEVEL_HIGH>,
			     <GIC_SPI 175 IRQ_TYPE_LEVEL_HIGH>,
			     <GIC_SPI 176 IRQ_TYPE_LEVEL_HIGH>,
			     <GIC_SPI 361 IRQ_TYPE_LEVEL_HIGH>;
		clocks = <&cru PCLK_HDMITX1>,
			 <&cru CLK_HDMIHDP1>,
			 <&cru CLK_HDMITX1_EARC>,
			 <&cru CLK_HDMITX1_REF>,
			 <&cru MCLK_I2S6_8CH_TX>,
			 <&cru DCLK_VOP0>,
			 <&cru DCLK_VOP1>,
			 <&cru DCLK_VOP2>,
			 <&cru DCLK_VOP3>,
			 <&hclk_vo1>,
			 <&hdptxphy_hdmi1>;
		clock-names = "pclk",
			      "hpd",
			      "earc",
			      "hdmitx_ref",
			      "aud",
			      "dclk_vp0",
			      "dclk_vp1",
			      "dclk_vp2",
			      "dclk_vp3",
			      "hclk_vo1",
			      "link_clk";
		resets = <&cru SRST_HDMITX1_REF>, <&cru SRST_HDMIHDP1>;
		reset-names = "ref", "hdp";
		power-domains = <&power RK3588_PD_VO1>;
		pinctrl-names = "default";
		pinctrl-0 = <&hdmim2_tx1_cec &hdmim0_tx1_hpd &hdmim1_tx1_scl &hdmim1_tx1_sda>;
		reg-io-width = <4>;
		rockchip,grf = <&sys_grf>;
		rockchip,vo1_grf = <&vo1_grf>;
		phys = <&hdptxphy_hdmi1>;
		phy-names = "hdmi";
		#sound-dai-cells = <0>;
		status = "disabled";

		ports {
			#address-cells = <1>;
			#size-cells = <0>;

			hdmi1_in: port@0 {
				reg = <0>;
				#address-cells = <1>;
				#size-cells = <0>;

				hdmi1_in_vp0: endpoint@0 {
					reg = <0>;
					remote-endpoint = <&vp0_out_hdmi1>;
					status = "disabled";
				};

				hdmi1_in_vp1: endpoint@1 {
					reg = <1>;
					remote-endpoint = <&vp1_out_hdmi1>;
					status = "disabled";
				};

				hdmi1_in_vp2: endpoint@2 {
					reg = <2>;
					remote-endpoint = <&vp2_out_hdmi1>;
					status = "disabled";
				};
			};
		};
	};

	edp1: edp@fded0000 {
		compatible = "rockchip,rk3588-edp";
		reg = <0x0 0xfded0000 0x0 0x1000>;
		interrupts = <GIC_SPI 164 IRQ_TYPE_LEVEL_HIGH>;
		clocks = <&cru CLK_EDP1_24M>, <&cru PCLK_EDP1>,
			 <&cru CLK_EDP1_200M>, <&hclk_vo1>;
		clock-names = "dp", "pclk", "spdif", "hclk";
		resets = <&cru SRST_EDP1_24M>, <&cru SRST_P_EDP1>;
		reset-names = "dp", "apb";
		phys = <&hdptxphy1>;
		phy-names = "dp";
		power-domains = <&power RK3588_PD_VO1>;
		rockchip,grf = <&vo1_grf>;
		#sound-dai-cells = <1>;
		status = "disabled";

		ports {
			#address-cells = <1>;
			#size-cells = <0>;

			port@0 {
				reg = <0>;
				#address-cells = <1>;
				#size-cells = <0>;

				edp1_in_vp0: endpoint@0 {
					reg = <0>;
					remote-endpoint = <&vp0_out_edp1>;
					status = "disabled";
				};

				edp1_in_vp1: endpoint@1 {
					reg = <1>;
					remote-endpoint = <&vp1_out_edp1>;
					status = "disabled";
				};

				edp1_in_vp2: endpoint@2 {
					reg = <2>;
					remote-endpoint = <&vp2_out_edp1>;
					status = "disabled";
				};
			};

			port@1 {
				reg = <1>;

				edp1_out: endpoint { };
			};
		};
	};

	hdmirx_ctrler: hdmirx-controller@fdee0000 {
		compatible = "rockchip,rk3588-hdmirx-ctrler", "rockchip,hdmirx-ctrler";
		reg = <0x0 0xfdee0000 0x0 0x6000>;
		reg-names = "hdmirx_regs";
		power-domains = <&power RK3588_PD_VO1>;
		rockchip,grf = <&sys_grf>;
		rockchip,vo1_grf = <&vo1_grf>;
		interrupts = <GIC_SPI 177 IRQ_TYPE_LEVEL_HIGH>,
			     <GIC_SPI 436 IRQ_TYPE_LEVEL_HIGH>,
			     <GIC_SPI 179 IRQ_TYPE_LEVEL_HIGH>;
		interrupt-names = "cec", "hdmi", "dma";
		clocks = <&cru ACLK_HDMIRX>,
			 <&cru CLK_HDMIRX_AUD>,
			 <&cru CLK_CR_PARA>,
			 <&cru PCLK_HDMIRX>,
			 <&cru CLK_HDMIRX_REF>,
			 <&cru PCLK_S_HDMIRX>,
			 <&hclk_vo1>;
		clock-names = "aclk",
			      "audio",
			      "cr_para",
			      "pclk",
			      "ref",
			      "hclk_s_hdmirx",
			      "hclk_vo1";
		resets = <&cru SRST_A_HDMIRX>, <&cru SRST_P_HDMIRX>,
			 <&cru SRST_HDMIRX_REF>, <&cru SRST_A_HDMIRX_BIU>;
		reset-names = "rst_a", "rst_p", "rst_ref", "rst_biu";
		pinctrl-0 = <&hdmim1_rx_cec &hdmim1_rx_hpdin &hdmim1_rx_scl &hdmim1_rx_sda>;
		pinctrl-names = "default";
		status = "disabled";
	};

	sata1: sata@fe220000 {
		compatible = "rockchip,rk-ahci", "snps,dwc-ahci";
		reg = <0 0xfe220000 0 0x1000>;
		clocks = <&cru ACLK_SATA1>, <&cru CLK_PMALIVE1>,
			 <&cru CLK_RXOOB1>, <&cru CLK_PIPEPHY1_REF>,
			 <&cru CLK_PIPEPHY1_PIPE_ASIC_G>;
		clock-names = "sata", "pmalive", "rxoob", "ref", "asic";
		interrupts = <GIC_SPI 274 IRQ_TYPE_LEVEL_HIGH>;
		interrupt-names = "hostc";
		phys = <&combphy1_ps PHY_TYPE_SATA>;
		phy-names = "sata-phy";
		ports-implemented = <0x1>;
		status = "disabled";
	};

	hdptxphy1: phy@fed70000 {
		compatible = "rockchip,rk3588-hdptx-phy";
		reg = <0x0 0xfed70000 0x0 0x2000>;
		clocks = <&cru CLK_USB2PHY_HDPTXRXPHY_REF>, <&cru PCLK_HDPTX1>;
		clock-names = "ref", "apb";
		resets = <&cru SRST_P_HDPTX1>, <&cru SRST_HDPTX1_INIT>,
			 <&cru SRST_HDPTX1_CMN>, <&cru SRST_HDPTX1_LANE>;
		reset-names = "apb", "init", "cmn", "lane";
		rockchip,grf = <&hdptxphy1_grf>;
		#phy-cells = <0>;
		status = "disabled";
	};

	hdptxphy_hdmi1: hdmiphy@fed70000 {
		compatible = "rockchip,rk3588-hdptx-phy-hdmi";
		reg = <0x0 0xfed70000 0x0 0x2000>;
		clocks = <&cru CLK_USB2PHY_HDPTXRXPHY_REF>, <&cru PCLK_HDPTX1>;
		clock-names = "ref", "apb";
		clock-output-names = "clk_hdmiphy_pixel1";
		#clock-cells = <0>;
		resets = <&cru SRST_HDPTX1>, <&cru SRST_P_HDPTX1>,
			 <&cru SRST_HDPTX1_INIT>, <&cru SRST_HDPTX1_CMN>,
			 <&cru SRST_HDPTX1_LANE>, <&cru SRST_HDPTX1_ROPLL>,
			 <&cru SRST_HDPTX1_LCPLL>;
		reset-names = "phy", "apb", "init", "cmn", "lane", "ropll",
			      "lcpll";
		rockchip,grf = <&hdptxphy1_grf>;
		#phy-cells = <0>;
		status = "disabled";
	};

	usbdp_phy1: phy@fed90000 {
		compatible = "rockchip,rk3588-usbdp-phy";
		reg = <0x0 0xfed90000 0x0 0x10000>;
		rockchip,u2phy-grf = <&usb2phy1_grf>;
		rockchip,usb-grf = <&usb_grf>;
		rockchip,usbdpphy-grf = <&usbdpphy1_grf>;
		rockchip,vo-grf = <&vo0_grf>;
		clocks = <&cru CLK_USBDPPHY_MIPIDCPPHY_REF>,
			 <&cru CLK_USBDP_PHY1_IMMORTAL>,
			 <&cru PCLK_USBDPPHY1>,
			 <&u2phy1>;
		clock-names = "refclk", "immortal", "pclk", "utmi";
		resets = <&cru SRST_USBDP_COMBO_PHY1_INIT>,
			 <&cru SRST_USBDP_COMBO_PHY1_CMN>,
			 <&cru SRST_USBDP_COMBO_PHY1_LANE>,
			 <&cru SRST_USBDP_COMBO_PHY1_PCS>,
			 <&cru SRST_P_USBDPPHY1>;
		reset-names = "init", "cmn", "lane", "pcs_apb", "pma_apb";
		status = "disabled";

		usbdp_phy1_dp: dp-port {
			#phy-cells = <0>;
			status = "disabled";
		};

		usbdp_phy1_u3: u3-port {
			#phy-cells = <0>;
			status = "disabled";
		};
	};





};

&display_subsystem {
	memory-region = <&drm_logo>;
	memory-region-names = "drm-logo";
	route {
		route_dp1: route-dp1 {
			status = "disabled";
			logo,uboot = "logo.bmp";
			logo,kernel = "logo_kernel.bmp";
			logo,mode = "center";
			charge_logo,mode = "center";
			connect = <&vp1_out_dp1>;
		};

		route_hdmi1: route-hdmi1 {
			status = "disabled";
			logo,uboot = "logo.bmp";
			logo,kernel = "logo_kernel.bmp";
			logo,mode = "center";
			charge_logo,mode = "center";
			connect = <&vp1_out_hdmi1>;
		};
	};
};

&dfi {
	status = "okay";
};

&dmc {
	status = "okay";
	center-supply = <&vdd_ddr_s0>;
	mem-supply = <&vdd_log_s0>;
};

&rng {
	status = "okay";
};

&vp0 {
	vp0_out_dp1: endpoint@3 {
		reg = <3>;
		remote-endpoint = <&dp1_in_vp0>;
	};

	vp0_out_edp1: endpoint@4 {
		reg = <4>;
		remote-endpoint = <&edp1_in_vp0>;
	};

	vp0_out_hdmi1: endpoint@5 {
		reg = <5>;
		remote-endpoint = <&hdmi1_in_vp0>;
	};
};

&vp1 {
	vp1_out_dp1: endpoint@3 {
		reg = <3>;
		remote-endpoint = <&dp1_in_vp1>;
	};

	vp1_out_edp1: endpoint@4 {
		reg = <4>;
		remote-endpoint = <&edp1_in_vp1>;
	};

	vp1_out_hdmi1: endpoint@5 {
		reg = <5>;
		remote-endpoint = <&hdmi1_in_vp1>;
	};
};

&vp2 {
	vp2_out_dp1: endpoint@5 {
		reg = <5>;
		remote-endpoint = <&dp1_in_vp2>;
	};

	vp2_out_edp1: endpoint@6 {
		reg = <6>;
		remote-endpoint = <&edp1_in_vp2>;
	};

	vp2_out_hdmi1: endpoint@7 {
		reg = <7>;
		remote-endpoint = <&hdmi1_in_vp2>;
	};
};

#include "rk3588-base-pinctrl.dtsi"
